VERSION ""

NS_ :

BS_:

BU_:
VAL_TABLE_ TIM_AuthErrorCode 39 "LwAPossibleBitMismatch" 38 "AuthenticationAbortedDueToGeneralPeerError" 37 "AuthenticationAbortedByPeerDueToError" 36 "ChallengeDataCorrupt" 35 "InvalidChallengeLength" 34 "FunctionFacilityNotCertified" 33 "RequestNotAllowed" 32 "Reserved_0x20" 31 "AuthenticationTimeout" 30 "CertificateTypeInvalid" 29 "DeviceCertificateRevoked" 28 "ManufacturerSeriesCertificateRevoked" 27 "ManufacturerCertificateRevoked" 26 "LabCertificateRevoked" 25 "RootCertificateRevoked" 24 "CertificateTypeMismatch" 23 "CertificateChainInvalid" 22 "ECU_CCID_Mismatch" 21 "NAME_Mismatch" 20 "ECC_PublicKeyValidationFailed" 19 "UnexpectedRestartAuthenticationBitSet" 18 "AuthenticationStatusInvalid" 17 "AuthenticationTypeNotSupported" 16 "AuthenticationStatusLost" 15 "DeviceCertificateDataCorrupt" 14 "ManufacturerSeriesCertificateDataCorrupt" 13 "ManufacturerCertificateDataCorrupt" 12 "TestLabCertificateDataCorrupt" 11 "RootCertificateDataCorrupt" 10 "InternalError" 9 "ChallengesDontMatch" 8 "DeviceCertificateSignatureInvalid" 7 "ManufacturerSeriesCertificateSignatureInvalid" 6 "ManufacturerCertificateSignatureInvalid" 5 "LabCertificateSignatureInvalid" 4 "RootCertificateSignatureInvalid" 3 "NotAuthenticationServerOrClient" 2 "CertificateFormatNotSupported" 1 "ParticipantBusy" 0 "NoError" ;
VAL_TABLE_ TIM_CertificateType 255 "NotAvailable" 6 "CRLCertificate" 5 "CRLSigningCertificate" 4 "DeviceCertificate" 3 "ManufacturerSeriesCertificate" 2 "ManufacturerCertificate" 1 "TestlabCertificate" 0 "AEFRootCertificate" ;
VAL_TABLE_ NetworkInterconnUnitParametrics 16 "NetworkInterconnectionUnitType" 15 "NumberOfPorts" 14 "UptimeSinceLastPowerOnReset " 13 "AverageNumOfMsgsFilteredPerSec" 12 "AverageNumOfMsgsForwardedPerSec" 11 "AverageNumOfMsgsReceivedPerSec" 10 "NumOfMsgsWithExcessTransitDelayTime " 9 "NumOfMsgsLostDueToBufferOverflow " 8 "AverageTransitDelayTime" 7 "MaxTransitDelayTime" 6 "MaxNumOfMsgsFilteredPerSec" 5 "MaxNumOfMsgsForwardedPerSec" 4 "MaxNumOfMsgsReceivedPerSec" 3 "NumberOfFilterDatabaseEntries" 2 "MaxFilterDatabaseSize" 1 "BufferSize" 0 "RequestAllParameters" ;
VAL_TABLE_ FMI 0 "Above normal (most severe)" 1 "Below normal (most severe)" 2 "Data erratic" 3 "Voltage above normal" 4 "Voltage below normal" 5 "Current below normal" 6 "Current above normal" 7 "Mechanical system not responding" 8 "Abnormal frequency" 9 "Abnormal update rate" 10 "Abnormal rate of change" 11 "Root cause not known" 12 "Bad intelligent device" 13 "Out of calibration" 14 "Special intstructions" 15 "Above normal (least severe)" 16 "Above normal (moderately severe)" 17 "Below normal (least severe)" 18 "Below normal (moderately severe)" 19 "Received network data in error" 31 "Condition exists" 20 "Data drifted high" 21 "Data drifted low" ;

BO_ 3221225472 VECTOR__INDEPENDENT_SIG_MSG: 0 Vector__XXX
 SG_ ISO15765_3 : 0|1@1+ (1,0) [0|1] "" Vector__XXX
 SG_ ISO14230 : 0|1@1+ (1,0) [0|1] "" Vector__XXX
 SG_ J1939_73 : 0|1@1+ (1,0) [0|1] "" Vector__XXX

BO_ 2566835198 DM2: 22 Vector__XXX
 SG_ SPN_High4 : 133|3@1+ (1,0) [0|7] "" Vector__XXX
 SG_ SPN_High3 : 101|3@1+ (1,0) [0|7] "" Vector__XXX
 SG_ SPN_High5 : 165|3@1+ (1,0) [0|7] "" Vector__XXX
 SG_ SPN_High2 : 69|3@1+ (1,0) [0|7] "" Vector__XXX
 SG_ SPN_High1 : 37|3@1+ (1,0) [0|7] "" Vector__XXX
 SG_ SpnConversionMethod1 : 47|1@1+ (1,0) [0|1] "" Vector__XXX
 SG_ SpnConversionMethod5 : 175|1@1+ (1,0) [0|1] "" Vector__XXX
 SG_ SpnConversionMethod4 : 143|1@1+ (1,0) [0|1] "" Vector__XXX
 SG_ SpnConversionMethod3 : 111|1@1+ (1,0) [0|1] "" Vector__XXX
 SG_ SpnConversionMethod2 : 79|1@1+ (1,0) [0|1] "" Vector__XXX
 SG_ OccurenceCount5 : 168|7@1+ (1,0) [0|127] "" Vector__XXX
 SG_ OccurenceCount4 : 136|7@1+ (1,0) [0|127] "" Vector__XXX
 SG_ OccurenceCount3 : 104|7@1+ (1,0) [0|127] "" Vector__XXX
 SG_ OccurenceCount2 : 72|7@1+ (1,0) [0|127] "" Vector__XXX
 SG_ OccurenceCount1 : 40|7@1+ (1,0) [0|127] "" Vector__XXX
 SG_ FMI5 : 160|5@1+ (1,0) [0|31] "" Vector__XXX
 SG_ FMI4 : 128|5@1+ (1,0) [0|31] "" Vector__XXX
 SG_ FMI3 : 96|5@1+ (1,0) [0|31] "" Vector__XXX
 SG_ FMI2 : 64|5@1+ (1,0) [0|31] "" Vector__XXX
 SG_ FMI1 : 32|5@1+ (1,0) [0|31] "" Vector__XXX
 SG_ SPN5 : 144|16@1+ (1,0) [0|524287] "" Vector__XXX
 SG_ SPN4 : 112|16@1+ (1,0) [0|524287] "" Vector__XXX
 SG_ SPN3 : 80|16@1+ (1,0) [0|524287] "" Vector__XXX
 SG_ SPN2 : 48|16@1+ (1,0) [0|524287] "" Vector__XXX
 SG_ SPN1 : 16|16@1+ (1,0) [0|524287] "" Vector__XXX

BO_ 2566834942 DM1: 22 Vector__XXX
 SG_ SPN_High4 : 133|3@1+ (1,0) [0|7] "" Vector__XXX
 SG_ SPN_High3 : 101|3@1+ (1,0) [0|7] "" Vector__XXX
 SG_ SPN_High5 : 165|3@1+ (1,0) [0|7] "" Vector__XXX
 SG_ SPN_High2 : 69|3@1+ (1,0) [0|7] "" Vector__XXX
 SG_ SPN_High1 : 37|3@1+ (1,0) [0|7] "" Vector__XXX
 SG_ SpnConversionMethod1 : 47|1@1+ (1,0) [0|1] "" Vector__XXX
 SG_ SpnConversionMethod5 : 175|1@1+ (1,0) [0|1] "" Vector__XXX
 SG_ SpnConversionMethod4 : 143|1@1+ (1,0) [0|1] "" Vector__XXX
 SG_ SpnConversionMethod3 : 111|1@1+ (1,0) [0|1] "" Vector__XXX
 SG_ SpnConversionMethod2 : 79|1@1+ (1,0) [0|1] "" Vector__XXX
 SG_ OccurenceCount5 : 168|7@1+ (1,0) [0|127] "" Vector__XXX
 SG_ OccurenceCount4 : 136|7@1+ (1,0) [0|127] "" Vector__XXX
 SG_ OccurenceCount3 : 104|7@1+ (1,0) [0|127] "" Vector__XXX
 SG_ OccurenceCount2 : 72|7@1+ (1,0) [0|127] "" Vector__XXX
 SG_ OccurenceCount1 : 40|7@1+ (1,0) [0|127] "" Vector__XXX
 SG_ FMI5 : 160|5@1+ (1,0) [0|31] "" Vector__XXX
 SG_ FMI4 : 128|5@1+ (1,0) [0|31] "" Vector__XXX
 SG_ FMI3 : 96|5@1+ (1,0) [0|31] "" Vector__XXX
 SG_ FMI2 : 64|5@1+ (1,0) [0|31] "" Vector__XXX
 SG_ FMI1 : 32|5@1+ (1,0) [0|31] "" Vector__XXX
 SG_ SPN5 : 144|16@1+ (1,0) [0|524287] "" Vector__XXX
 SG_ SPN4 : 112|16@1+ (1,0) [0|524287] "" Vector__XXX
 SG_ SPN3 : 80|16@1+ (1,0) [0|524287] "" Vector__XXX
 SG_ SPN2 : 48|16@1+ (1,0) [0|524287] "" Vector__XXX
 SG_ SPN1 : 16|16@1+ (1,0) [0|524287] "" Vector__XXX

BO_ 2566655998 SHRPS: 8 Vector__XXX
 SG_ FrontHitchPitchSensitivity : 8|8@1+ (0.4,0) [0|100] "%" Vector__XXX
 SG_ FrontHitchRollSensitivity : 0|8@1+ (0.4,0) [0|100] "%" Vector__XXX

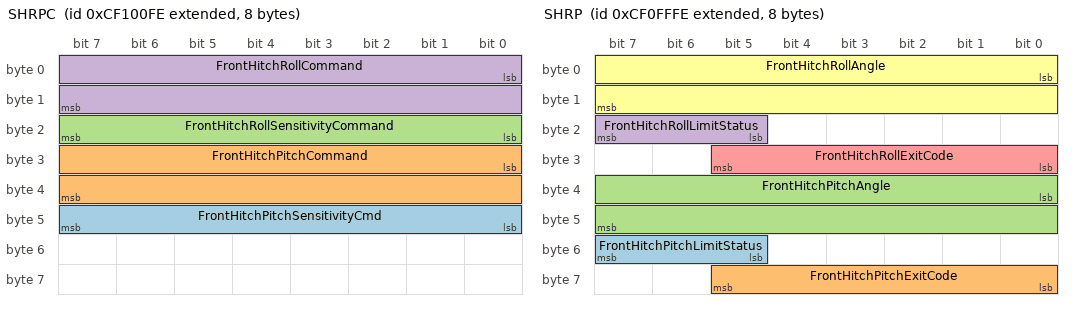
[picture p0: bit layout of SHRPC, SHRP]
BO_ 2364604670 SHRPC: 8 Vector__XXX
 SG_ FrontHitchPitchSensitivityCmd : 40|8@1+ (0.4,0) [0|100] "%" Vector__XXX
 SG_ FrontHitchPitchCommand : 24|16@1+ (0.002,-64) [-64|64.51] "deg" Vector__XXX
 SG_ FrontHitchRollSensitivityCommand : 16|8@1+ (0.4,0) [0|100] "%" Vector__XXX
 SG_ FrontHitchRollCommand : 0|16@1+ (0.002,-64) [-64|64.51] "deg" Vector__XXX

BO_ 2364604414 SHRP: 8 Vector__XXX
 SG_ FrontHitchPitchLimitStatus : 53|3@1+ (1,0) [0|7] "" Vector__XXX
 SG_ FrontHitchPitchExitCode : 56|6@1+ (1,0) [0|63] "" Vector__XXX
 SG_ FrontHitchPitchAngle : 32|16@1+ (0.002,-64) [-64|64.51] "deg" Vector__XXX
 SG_ FrontHitchRollLimitStatus : 21|3@1+ (1,0) [0|7] "" Vector__XXX
 SG_ FrontHitchRollExitCode : 24|6@1+ (1,0) [0|63] "" Vector__XXX
 SG_ FrontHitchRollAngle : 0|16@1+ (0.002,-64) [-64|64.51] "deg" Vector__XXX

BO_ 2566655742 PHRPS: 8 Vector__XXX
 SG_ RearHitchPitchSensitivity : 8|8@1+ (0.4,0) [0|100] "%" Vector__XXX
 SG_ RearHitchRollSensitivity : 0|8@1+ (0.4,0) [0|100] "%" Vector__XXX

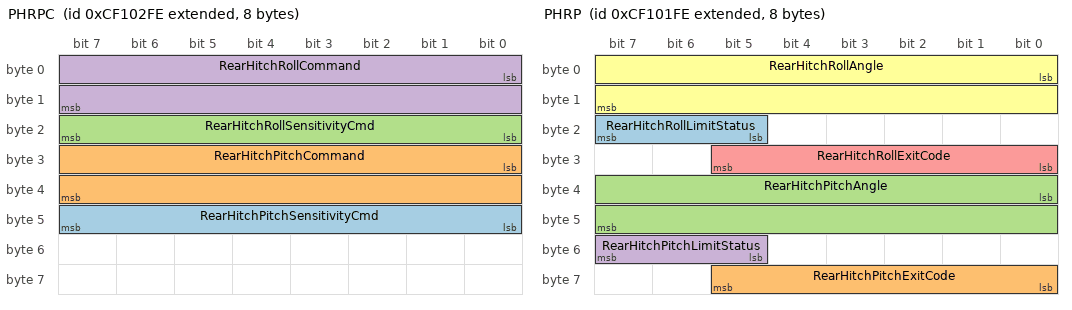
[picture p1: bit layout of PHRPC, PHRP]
BO_ 2364605182 PHRPC: 8 Vector__XXX
 SG_ RearHitchPitchSensitivityCmd : 40|8@1+ (0.4,0) [0|100] "%" Vector__XXX
 SG_ RearHitchPitchCommand : 24|16@1+ (0.002,-64) [-64|64.51] "deg" Vector__XXX
 SG_ RearHitchRollSensitivityCmd : 16|8@1+ (0.4,0) [0|100] "%" Vector__XXX
 SG_ RearHitchRollCommand : 0|16@1+ (0.002,-64) [-64|64.51] "deg" Vector__XXX

BO_ 2364604926 PHRP: 8 Vector__XXX
 SG_ RearHitchRollLimitStatus : 21|3@1+ (1,0) [0|7] "" Vector__XXX
 SG_ RearHitchPitchExitCode : 56|6@1+ (1,0) [0|63] "" Vector__XXX
 SG_ RearHitchPitchAngle : 32|16@1+ (0.002,-64) [-64|64.51] "deg" Vector__XXX
 SG_ RearHitchPitchLimitStatus : 53|3@1+ (1,0) [0|7] "" Vector__XXX
 SG_ RearHitchRollExitCode : 24|6@1+ (1,0) [0|0] "" Vector__XXX
 SG_ RearHitchRollAngle : 0|16@1+ (0.002,-64) [-64|64.51] "deg" Vector__XXX

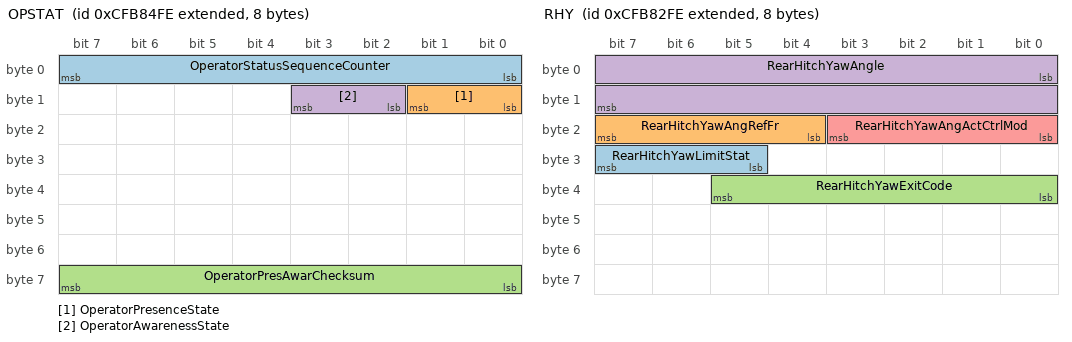
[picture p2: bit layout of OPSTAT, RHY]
BO_ 2365293822 OPSTAT: 8 Vector__XXX
 SG_ OperatorStatusSequenceCounter : 0|8@1+ (1,0) [0|255] "" Vector__XXX
 SG_ OperatorPresenceState : 8|2@1+ (1,0) [0|0] "" Vector__XXX
 SG_ OperatorPresAwarChecksum : 56|8@1+ (1,0) [0|255] "" Vector__XXX
 SG_ OperatorAwarenessState : 10|2@1+ (1,0) [0|3] "" Vector__XXX

BO_ 2365293310 RHY: 8 Vector__XXX
 SG_ RearHitchYawLimitStat : 29|3@1+ (1,0) [0|7] "" Vector__XXX
 SG_ RearHitchYawAngRefFr : 20|4@1+ (1,0) [0|15] "" Vector__XXX
 SG_ RearHitchYawExitCode : 32|6@1+ (1,0) [0|63] "" Vector__XXX
 SG_ RearHitchYawAngle : 0|16@1+ (0.0078125,-200) [-200|200] "deg" Vector__XXX
 SG_ RearHitchYawAngActCtrlMod : 16|4@1+ (1,0) [0|15] "" Vector__XXX

BO_ 2364620542 FHYC: 8 Vector__XXX
 SG_ FrontHitchYawCommand : 0|16@1+ (0.0078125,-200) [-200|200] "deg" Vector__XXX

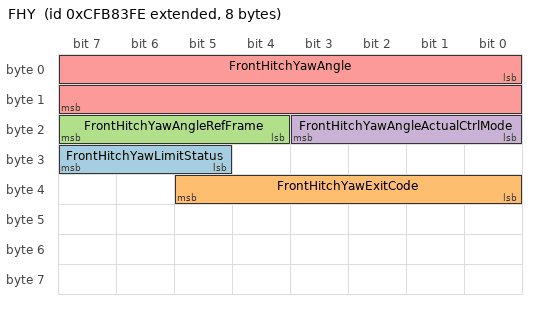
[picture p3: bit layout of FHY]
BO_ 2365293566 FHY: 8 Vector__XXX
 SG_ FrontHitchYawLimitStatus : 29|3@1+ (1,0) [0|7] "" Vector__XXX
 SG_ FrontHitchYawExitCode : 32|6@1+ (1,0) [0|63] "" Vector__XXX
 SG_ FrontHitchYawAngleRefFrame : 20|4@1+ (1,0) [0|15] "" Vector__XXX
 SG_ FrontHitchYawAngleActualCtrlMode : 16|4@1+ (1,0) [0|15] "" Vector__XXX
 SG_ FrontHitchYawAngle : 0|16@1+ (0.0078125,-200) [-200|200] "deg" Vector__XXX

BO_ 2566730494 ECUDP: 8 Vector__XXX
 SG_ DiagProtocolIdentification : 0|8@1+ (1,0) [0|255] "" Vector__XXX

BO_ 2625437438 ECFF: 8 Vector__XXX

BO_ 2364620798 RHYC: 8 Vector__XXX
 SG_ RearHitchYawCommand : 0|16@1+ (0.0078125,-200) [-200|200] "deg" Vector__XXX

BO_ 2621308670 TIM21_CS: 16 Vector__XXX
 SG_ VSpeedIncAggressivenessReq_VS m65 : 16|16@1+ (0.001,0) [0|64.255] "m/s per sec." Vector__XXX
 SG_ VSpeedDecAggressivenessReq_VS m65 : 32|16@1+ (0.001,0) [0|64.255] "m/s per sec." Vector__XXX
 SG_ RSpeedIncAggressivenessReq_RPTO m65 : 16|16@1+ (0.125,0) [0|8031.875] "1/min per sec." Vector__XXX
 SG_ RSpeedIncAggressivenessReq_FPTO m65 : 16|16@1+ (0.125,0) [0|8031.875] "1/min per sec." Vector__XXX
 SG_ RSpeedDecAggressivenessReq_RPTO m65 : 32|16@1+ (0.125,0) [0|8031.875] "1/min per sec." Vector__XXX
 SG_ RSpeedDecAggressivenessReq_FPTO m65 : 32|16@1+ (0.125,0) [0|8031.875] "1/min per sec." Vector__XXX
 SG_ PositionIncAggressivenessReq_RTL m65 : 16|16@1+ (0.01,0) [0|100] "% per sec." Vector__XXX
 SG_ PositionIncAggressivenessReq_RH m65 : 16|16@1+ (0.01,0) [0|100] "% per sec." Vector__XXX
 SG_ PositionIncAggressivenessReq_FTL m65 : 16|16@1+ (0.01,0) [0|100] "% per sec." Vector__XXX
 SG_ PositionIncAggressivenessReq_FH m65 : 16|16@1+ (0.01,0) [0|100] "% per sec." Vector__XXX
 SG_ PositionDecAggressivenessReq_RTL m65 : 32|16@1+ (0.01,0) [0|100] "% per sec." Vector__XXX
 SG_ PositionDecAggressivenessReq_RH m65 : 32|16@1+ (0.01,0) [0|100] "% per sec." Vector__XXX
 SG_ PositionDecAggressivenessReq_FTL m65 : 32|16@1+ (0.01,0) [0|100] "% per sec." Vector__XXX
 SG_ PositionDecAggressivenessReq_FH m65 : 32|16@1+ (0.01,0) [0|100] "% per sec." Vector__XXX
 SG_ FlowIncAggressivenessReq_AV32 m65 : 16|16@1+ (0.004,0) [0|257.016] "% per sec." Vector__XXX
 SG_ FlowIncAggressivenessReq_AV31 m65 : 16|16@1+ (0.004,0) [0|257.016] "% per sec." Vector__XXX
 SG_ FlowIncAggressivenessReq_AV30 m65 : 16|16@1+ (0.004,0) [0|257.016] "% per sec." Vector__XXX
 SG_ FlowIncAggressivenessReq_AV29 m65 : 16|16@1+ (0.004,0) [0|257.016] "% per sec." Vector__XXX
 SG_ FlowIncAggressivenessReq_AV28 m65 : 16|16@1+ (0.004,0) [0|257.016] "% per sec." Vector__XXX
 SG_ FlowIncAggressivenessReq_AV27 m65 : 16|16@1+ (0.004,0) [0|257.016] "% per sec." Vector__XXX
 SG_ FlowIncAggressivenessReq_AV26 m65 : 16|16@1+ (0.004,0) [0|257.016] "% per sec." Vector__XXX
 SG_ FlowIncAggressivenessReq_AV25 m65 : 16|16@1+ (0.004,0) [0|257.016] "% per sec." Vector__XXX
 SG_ FlowIncAggressivenessReq_AV24 m65 : 16|16@1+ (0.004,0) [0|257.016] "% per sec." Vector__XXX
 SG_ FlowIncAggressivenessReq_AV23 m65 : 16|16@1+ (0.004,0) [0|257.016] "% per sec." Vector__XXX
 SG_ FlowIncAggressivenessReq_AV22 m65 : 16|16@1+ (0.004,0) [0|257.016] "% per sec." Vector__XXX
 SG_ FlowIncAggressivenessReq_AV21 m65 : 16|16@1+ (0.004,0) [0|257.016] "% per sec." Vector__XXX
 SG_ FlowIncAggressivenessReq_AV20 m65 : 16|16@1+ (0.004,0) [0|257.016] "% per sec." Vector__XXX
 SG_ FlowIncAggressivenessReq_AV19 m65 : 16|16@1+ (0.004,0) [0|257.016] "% per sec." Vector__XXX
 SG_ FlowIncAggressivenessReq_AV18 m65 : 16|16@1+ (0.004,0) [0|257.016] "% per sec." Vector__XXX
 SG_ FlowIncAggressivenessReq_AV17 m65 : 16|16@1+ (0.004,0) [0|257.016] "% per sec." Vector__XXX
 SG_ FlowIncAggressivenessReq_AV16 m65 : 16|16@1+ (0.004,0) [0|257.016] "% per sec." Vector__XXX
 SG_ FlowIncAggressivenessReq_AV15 m65 : 16|16@1+ (0.004,0) [0|257.016] "% per sec." Vector__XXX
 SG_ FlowIncAggressivenessReq_AV14 m65 : 16|16@1+ (0.004,0) [0|257.016] "% per sec." Vector__XXX
 SG_ FlowIncAggressivenessReq_AV13 m65 : 16|16@1+ (0.004,0) [0|257.016] "% per sec." Vector__XXX
 SG_ FlowIncAggressivenessReq_AV12 m65 : 16|16@1+ (0.004,0) [0|257.016] "% per sec." Vector__XXX
 SG_ FlowIncAggressivenessReq_AV11 m65 : 16|16@1+ (0.004,0) [0|257.016] "% per sec." Vector__XXX
 SG_ FlowIncAggressivenessReq_AV10 m65 : 16|16@1+ (0.004,0) [0|257.016] "% per sec." Vector__XXX
 SG_ FlowIncAggressivenessReq_AV09 m65 : 16|16@1+ (0.004,0) [0|257.016] "% per sec." Vector__XXX
 SG_ FlowIncAggressivenessReq_AV08 m65 : 16|16@1+ (0.004,0) [0|257.016] "% per sec." Vector__XXX
 SG_ FlowIncAggressivenessReq_AV07 m65 : 16|16@1+ (0.004,0) [0|257.016] "% per sec." Vector__XXX
 SG_ FlowIncAggressivenessReq_AV06 m65 : 16|16@1+ (0.004,0) [0|257.016] "% per sec." Vector__XXX
 SG_ FlowIncAggressivenessReq_AV05 m65 : 16|16@1+ (0.004,0) [0|257.016] "% per sec." Vector__XXX
 SG_ FlowIncAggressivenessReq_AV04 m65 : 16|16@1+ (0.004,0) [0|257.016] "% per sec." Vector__XXX
 SG_ FlowIncAggressivenessReq_AV03 m65 : 16|16@1+ (0.004,0) [0|257.016] "% per sec." Vector__XXX
 SG_ FlowIncAggressivenessReq_AV02 m65 : 16|16@1+ (0.004,0) [0|257.016] "% per sec." Vector__XXX
 SG_ FlowIncAggressivenessReq_AV01 m65 : 16|16@1+ (0.004,0) [0|257.016] "% per sec." Vector__XXX
 SG_ FlowDecAggressivenessReq_AV32 m65 : 32|16@1+ (0.004,0) [0|257.016] "% per sec." Vector__XXX
 SG_ FlowDecAggressivenessReq_AV31 m65 : 32|16@1+ (0.004,0) [0|257.016] "% per sec." Vector__XXX
 SG_ FlowDecAggressivenessReq_AV30 m65 : 32|16@1+ (0.004,0) [0|257.016] "% per sec." Vector__XXX
 SG_ FlowDecAggressivenessReq_AV29 m65 : 32|16@1+ (0.004,0) [0|257.016] "% per sec." Vector__XXX
 SG_ FlowDecAggressivenessReq_AV28 m65 : 32|16@1+ (0.004,0) [0|257.016] "% per sec." Vector__XXX
 SG_ FlowDecAggressivenessReq_AV27 m65 : 32|16@1+ (0.004,0) [0|257.016] "% per sec." Vector__XXX
 SG_ FlowDecAggressivenessReq_AV26 m65 : 32|16@1+ (0.004,0) [0|257.016] "% per sec." Vector__XXX
 SG_ FlowDecAggressivenessReq_AV25 m65 : 32|16@1+ (0.004,0) [0|257.016] "% per sec." Vector__XXX
 SG_ FlowDecAggressivenessReq_AV24 m65 : 32|16@1+ (0.004,0) [0|257.016] "% per sec." Vector__XXX
 SG_ FlowDecAggressivenessReq_AV23 m65 : 32|16@1+ (0.004,0) [0|257.016] "% per sec." Vector__XXX
 SG_ FlowDecAggressivenessReq_AV22 m65 : 32|16@1+ (0.004,0) [0|257.016] "% per sec." Vector__XXX
 SG_ FlowDecAggressivenessReq_AV21 m65 : 32|16@1+ (0.004,0) [0|257.016] "% per sec." Vector__XXX
 SG_ FlowDecAggressivenessReq_AV20 m65 : 32|16@1+ (0.004,0) [0|257.016] "% per sec." Vector__XXX
 SG_ FlowDecAggressivenessReq_AV19 m65 : 32|16@1+ (0.004,0) [0|257.016] "% per sec." Vector__XXX
 SG_ FlowDecAggressivenessReq_AV18 m65 : 32|16@1+ (0.004,0) [0|257.016] "% per sec." Vector__XXX
 SG_ FlowDecAggressivenessReq_AV17 m65 : 32|16@1+ (0.004,0) [0|257.016] "% per sec." Vector__XXX
 SG_ FlowDecAggressivenessReq_AV16 m65 : 32|16@1+ (0.004,0) [0|257.016] "% per sec." Vector__XXX
 SG_ FlowDecAggressivenessReq_AV15 m65 : 32|16@1+ (0.004,0) [0|257.016] "% per sec." Vector__XXX
 SG_ FlowDecAggressivenessReq_AV14 m65 : 32|16@1+ (0.004,0) [0|257.016] "% per sec." Vector__XXX
 SG_ FlowDecAggressivenessReq_AV13 m65 : 32|16@1+ (0.004,0) [0|257.016] "% per sec." Vector__XXX
 SG_ FlowDecAggressivenessReq_AV12 m65 : 32|16@1+ (0.004,0) [0|257.016] "% per sec." Vector__XXX
 SG_ FlowDecAggressivenessReq_AV11 m65 : 32|16@1+ (0.004,0) [0|257.016] "% per sec." Vector__XXX
 SG_ FlowDecAggressivenessReq_AV10 m65 : 32|16@1+ (0.004,0) [0|257.016] "% per sec." Vector__XXX
 SG_ FlowDecAggressivenessReq_AV09 m65 : 32|16@1+ (0.004,0) [0|257.016] "% per sec." Vector__XXX
 SG_ FlowDecAggressivenessReq_AV08 m65 : 32|16@1+ (0.004,0) [0|257.016] "% per sec." Vector__XXX
 SG_ FlowDecAggressivenessReq_AV07 m65 : 32|16@1+ (0.004,0) [0|257.016] "% per sec." Vector__XXX
 SG_ FlowDecAggressivenessReq_AV06 m65 : 32|16@1+ (0.004,0) [0|257.016] "% per sec." Vector__XXX
 SG_ FlowDecAggressivenessReq_AV05 m65 : 32|16@1+ (0.004,0) [0|257.016] "% per sec." Vector__XXX
 SG_ FlowDecAggressivenessReq_AV04 m65 : 32|16@1+ (0.004,0) [0|257.016] "% per sec." Vector__XXX
 SG_ FlowDecAggressivenessReq_AV03 m65 : 32|16@1+ (0.004,0) [0|257.016] "% per sec." Vector__XXX
 SG_ FlowDecAggressivenessReq_AV02 m65 : 32|16@1+ (0.004,0) [0|257.016] "% per sec." Vector__XXX
 SG_ FlowDecAggressivenessReq_AV01 m65 : 32|16@1+ (0.004,0) [0|257.016] "% per sec." Vector__XXX
 SG_ CurvatureAggressivenessReq_EG m65 : 16|16@1+ (0.25,0) [0|16063.75] "1/km per sec." Vector__XXX
 SG_ SecurityByte_VS m17 : 56|8@1+ (1,0) [0|255] "" Vector__XXX
 SG_ SecurityByte_RTL m17 : 56|8@1+ (1,0) [0|255] "" Vector__XXX
 SG_ SecurityByte_RPTO m17 : 56|8@1+ (1,0) [0|255] "" Vector__XXX
 SG_ SecurityByte_RH m17 : 56|8@1+ (1,0) [0|255] "" Vector__XXX
 SG_ SecurityByte_FTL m17 : 56|8@1+ (1,0) [0|255] "" Vector__XXX
 SG_ SecurityByte_FPTO m17 : 56|8@1+ (1,0) [0|255] "" Vector__XXX
 SG_ SecurityByte_FH m17 : 56|8@1+ (1,0) [0|255] "" Vector__XXX
 SG_ SecurityByte_EG m17 : 56|8@1+ (1,0) [0|255] "" Vector__XXX
 SG_ SecurityByte_AV32 m17 : 56|8@1+ (1,0) [0|255] "" Vector__XXX
 SG_ SecurityByte_AV31 m17 : 56|8@1+ (1,0) [0|255] "" Vector__XXX
 SG_ SecurityByte_AV30 m17 : 56|8@1+ (1,0) [0|255] "" Vector__XXX
 SG_ SecurityByte_AV29 m17 : 56|8@1+ (1,0) [0|255] "" Vector__XXX
 SG_ SecurityByte_AV28 m17 : 56|8@1+ (1,0) [0|255] "" Vector__XXX
 SG_ SecurityByte_AV27 m17 : 56|8@1+ (1,0) [0|255] "" Vector__XXX
 SG_ SecurityByte_AV26 m17 : 56|8@1+ (1,0) [0|255] "" Vector__XXX
 SG_ SecurityByte_AV25 m17 : 56|8@1+ (1,0) [0|255] "" Vector__XXX
 SG_ SecurityByte_AV24 m17 : 56|8@1+ (1,0) [0|255] "" Vector__XXX
 SG_ SecurityByte_AV23 m17 : 56|8@1+ (1,0) [0|255] "" Vector__XXX
 SG_ SecurityByte_AV22 m17 : 56|8@1+ (1,0) [0|255] "" Vector__XXX
 SG_ SecurityByte_AV21 m17 : 56|8@1+ (1,0) [0|255] "" Vector__XXX
 SG_ SecurityByte_AV20 m17 : 56|8@1+ (1,0) [0|255] "" Vector__XXX
 SG_ SecurityByte_AV19 m17 : 56|8@1+ (1,0) [0|255] "" Vector__XXX
 SG_ SecurityByte_AV18 m17 : 56|8@1+ (1,0) [0|255] "" Vector__XXX
 SG_ SecurityByte_AV17 m17 : 56|8@1+ (1,0) [0|255] "" Vector__XXX
 SG_ SecurityByte_AV16 m17 : 56|8@1+ (1,0) [0|255] "" Vector__XXX
 SG_ SecurityByte_AV15 m17 : 56|8@1+ (1,0) [0|255] "" Vector__XXX
 SG_ SecurityByte_AV14 m17 : 56|8@1+ (1,0) [0|255] "" Vector__XXX
 SG_ SecurityByte_AV13 m17 : 56|8@1+ (1,0) [0|255] "" Vector__XXX
 SG_ SecurityByte_AV12 m17 : 56|8@1+ (1,0) [0|255] "" Vector__XXX
 SG_ SecurityByte_AV11 m17 : 56|8@1+ (1,0) [0|255] "" Vector__XXX
 SG_ SecurityByte_AV10 m17 : 56|8@1+ (1,0) [0|255] "" Vector__XXX
 SG_ SecurityByte_AV09 m17 : 56|8@1+ (1,0) [0|255] "" Vector__XXX
 SG_ SecurityByte_AV08 m17 : 56|8@1+ (1,0) [0|255] "" Vector__XXX
 SG_ SecurityByte_AV07 m17 : 56|8@1+ (1,0) [0|255] "" Vector__XXX
 SG_ SecurityByte_AV06 m17 : 56|8@1+ (1,0) [0|255] "" Vector__XXX
 SG_ SecurityByte_AV05 m17 : 56|8@1+ (1,0) [0|255] "" Vector__XXX
 SG_ SecurityByte_AV04 m17 : 56|8@1+ (1,0) [0|255] "" Vector__XXX
 SG_ SecurityByte_AV03 m17 : 56|8@1+ (1,0) [0|255] "" Vector__XXX
 SG_ SecurityByte_AV02 m17 : 56|8@1+ (1,0) [0|255] "" Vector__XXX
 SG_ SecurityByte_AV01 m17 : 56|8@1+ (1,0) [0|255] "" Vector__XXX
 SG_ PositionRequest_RTL m17 : 32|16@1+ (0.01,0) [0|100] "%" Vector__XXX
 SG_ PositionRequest_FTL m17 : 32|16@1+ (0.01,0) [0|100] "%" Vector__XXX
 SG_ ControlMode1_VS m0M : 24|4@1+ (1,0) [0|15] "" Vector__XXX
 SG_ ControlMode1_RTL m0M : 24|4@1+ (1,0) [0|15] "" Vector__XXX
 SG_ ControlMode1_FTL m0M : 24|4@1+ (1,0) [0|15] "" Vector__XXX
 SG_ NumOfControlModes_VS m0 : 16|4@1+ (1,0) [0|15] "" Vector__XXX
 SG_ NumOfControlModes_RTL m0 : 16|4@1+ (1,0) [0|15] "" Vector__XXX
 SG_ NumOfControlModes_FTL m0 : 16|4@1+ (1,0) [0|15] "" Vector__XXX
 SG_ NumOfBytes_CM1_VS m0 : 32|8@1+ (1,0) [0|255] "" Vector__XXX
 SG_ NumOfBytes_CM1_RTL m0 : 32|8@1+ (1,0) [0|255] "" Vector__XXX
 SG_ NumOfBytes_CM1_FTL m0 : 32|8@1+ (1,0) [0|255] "" Vector__XXX
 SG_ MsgType_RTL m72M : 8|8@1+ (1,0) [0|255] "" Vector__XXX
 SG_ MsgType_FTL m71M : 8|8@1+ (1,0) [0|255] "" Vector__XXX
 SG_ MsgType_EG m70M : 8|8@1+ (1,0) [0|255] "" Vector__XXX
 SG_ MsgType_VS m68M : 8|8@1+ (1,0) [0|255] "" Vector__XXX
 SG_ MsgType_RH m67M : 8|8@1+ (1,0) [0|255] "" Vector__XXX
 SG_ MsgType_FH m66M : 8|8@1+ (1,0) [0|255] "" Vector__XXX
 SG_ MsgType_RPTO m65M : 8|8@1+ (1,0) [0|255] "" Vector__XXX
 SG_ MsgType_FPTO m64M : 8|8@1+ (1,0) [0|255] "" Vector__XXX
 SG_ MsgType_AV32 m32M : 8|8@1+ (1,0) [0|255] "" Vector__XXX
 SG_ MsgType_AV31 m31M : 8|8@1+ (1,0) [0|255] "" Vector__XXX
 SG_ MsgType_AV30 m30M : 8|8@1+ (1,0) [0|255] "" Vector__XXX
 SG_ MsgType_AV29 m29M : 8|8@1+ (1,0) [0|255] "" Vector__XXX
 SG_ MsgType_AV28 m28M : 8|8@1+ (1,0) [0|255] "" Vector__XXX
 SG_ MsgType_AV27 m27M : 8|8@1+ (1,0) [0|255] "" Vector__XXX
 SG_ MsgType_AV26 m26M : 8|8@1+ (1,0) [0|255] "" Vector__XXX
 SG_ MsgType_AV25 m25M : 8|8@1+ (1,0) [0|255] "" Vector__XXX
 SG_ MsgType_AV24 m24M : 8|8@1+ (1,0) [0|255] "" Vector__XXX
 SG_ MsgType_AV23 m23M : 8|8@1+ (1,0) [0|255] "" Vector__XXX
 SG_ MsgType_AV22 m22M : 8|8@1+ (1,0) [0|255] "" Vector__XXX
 SG_ MsgType_AV21 m21M : 8|8@1+ (1,0) [0|255] "" Vector__XXX
 SG_ MsgType_AV20 m20M : 8|8@1+ (1,0) [0|255] "" Vector__XXX
 SG_ MsgType_AV19 m19M : 8|8@1+ (1,0) [0|255] "" Vector__XXX
 SG_ MsgType_AV18 m18M : 8|8@1+ (1,0) [0|255] "" Vector__XXX
 SG_ MsgType_AV17 m17M : 8|8@1+ (1,0) [0|255] "" Vector__XXX
 SG_ MsgType_AV16 m16M : 8|8@1+ (1,0) [0|255] "" Vector__XXX
 SG_ MsgType_AV15 m15M : 8|8@1+ (1,0) [0|255] "" Vector__XXX
 SG_ MsgType_AV14 m14M : 8|8@1+ (1,0) [0|255] "" Vector__XXX
 SG_ MsgType_AV13 m13M : 8|8@1+ (1,0) [0|255] "" Vector__XXX
 SG_ MsgType_AV12 m12M : 8|8@1+ (1,0) [0|255] "" Vector__XXX
 SG_ MsgType_AV11 m11M : 8|8@1+ (1,0) [0|255] "" Vector__XXX
 SG_ MsgType_AV10 m10M : 8|8@1+ (1,0) [0|255] "" Vector__XXX
 SG_ MsgType_AV09 m9M : 8|8@1+ (1,0) [0|255] "" Vector__XXX
 SG_ MsgType_AV08 m8M : 8|8@1+ (1,0) [0|255] "" Vector__XXX
 SG_ MsgType_AV07 m7M : 8|8@1+ (1,0) [0|255] "" Vector__XXX
 SG_ MsgType_AV06 m6M : 8|8@1+ (1,0) [0|255] "" Vector__XXX
 SG_ MsgType_AV05 m5M : 8|8@1+ (1,0) [0|255] "" Vector__XXX
 SG_ MsgType_AV04 m4M : 8|8@1+ (1,0) [0|255] "" Vector__XXX
 SG_ MsgType_AV03 m3M : 8|8@1+ (1,0) [0|255] "" Vector__XXX
 SG_ MsgType_AV02 m2M : 8|8@1+ (1,0) [0|255] "" Vector__XXX
 SG_ MsgType_AV01 m1M : 8|8@1+ (1,0) [0|255] "" Vector__XXX
 SG_ TIMFunctionID M : 0|8@1+ (1,0) [0|255] "" Vector__XXX
 SG_ FlowRequest_AV32 m17 : 32|16@1+ (0.004,-128.512) [0|0] "%" Vector__XXX
 SG_ FlowRequest_AV31 m17 : 32|16@1+ (0.004,-128.512) [0|0] "%" Vector__XXX
 SG_ FlowRequest_AV30 m17 : 32|16@1+ (0.004,-128.512) [0|0] "%" Vector__XXX
 SG_ FlowRequest_AV29 m17 : 32|16@1+ (0.004,-128.512) [0|0] "%" Vector__XXX
 SG_ FlowRequest_AV28 m17 : 32|16@1+ (0.004,-128.512) [0|0] "%" Vector__XXX
 SG_ FlowRequest_AV27 m17 : 32|16@1+ (0.004,-128.512) [0|0] "%" Vector__XXX
 SG_ FlowRequest_AV26 m17 : 32|16@1+ (0.004,-128.512) [0|0] "%" Vector__XXX
 SG_ FlowRequest_AV25 m17 : 32|16@1+ (0.004,-128.512) [0|0] "%" Vector__XXX
 SG_ FlowRequest_AV24 m17 : 32|16@1+ (0.004,-128.512) [0|0] "%" Vector__XXX
 SG_ FlowRequest_AV23 m17 : 32|16@1+ (0.004,-128.512) [0|0] "%" Vector__XXX
 SG_ FlowRequest_AV22 m17 : 32|16@1+ (0.004,-128.512) [0|0] "%" Vector__XXX
 SG_ FlowRequest_AV21 m17 : 32|16@1+ (0.004,-128.512) [0|0] "%" Vector__XXX
 SG_ FlowRequest_AV20 m17 : 32|16@1+ (0.004,-128.512) [0|0] "%" Vector__XXX
 SG_ FlowRequest_AV19 m17 : 32|16@1+ (0.004,-128.512) [0|0] "%" Vector__XXX
 SG_ FlowRequest_AV18 m17 : 32|16@1+ (0.004,-128.512) [0|0] "%" Vector__XXX
 SG_ FlowRequest_AV17 m17 : 32|16@1+ (0.004,-128.512) [0|0] "%" Vector__XXX
 SG_ FlowRequest_AV16 m17 : 32|16@1+ (0.004,-128.512) [0|0] "%" Vector__XXX
 SG_ FlowRequest_AV15 m17 : 32|16@1+ (0.004,-128.512) [0|0] "%" Vector__XXX
 SG_ FlowRequest_AV14 m17 : 32|16@1+ (0.004,-128.512) [0|0] "%" Vector__XXX
 SG_ FlowRequest_AV13 m17 : 32|16@1+ (0.004,-128.512) [0|0] "%" Vector__XXX
 SG_ FlowRequest_AV12 m17 : 32|16@1+ (0.004,-128.512) [0|0] "%" Vector__XXX
 SG_ FlowRequest_AV11 m17 : 32|16@1+ (0.004,-128.512) [0|0] "%" Vector__XXX
 SG_ FlowRequest_AV10 m17 : 32|16@1+ (0.004,-128.512) [0|0] "%" Vector__XXX
 SG_ FlowRequest_AV09 m17 : 32|16@1+ (0.004,-128.512) [0|0] "%" Vector__XXX
 SG_ FlowRequest_AV08 m17 : 32|16@1+ (0.004,-128.512) [0|0] "%" Vector__XXX
 SG_ FlowRequest_AV07 m17 : 32|16@1+ (0.004,-128.512) [0|0] "%" Vector__XXX
 SG_ FlowRequest_AV06 m17 : 32|16@1+ (0.004,-128.512) [0|0] "%" Vector__XXX
 SG_ FlowRequest_AV05 m17 : 32|16@1+ (0.004,-128.512) [0|0] "%" Vector__XXX
 SG_ FlowRequest_AV04 m17 : 32|16@1+ (0.004,-128.512) [0|0] "%" Vector__XXX
 SG_ FlowRequest_AV03 m17 : 32|16@1+ (0.004,-128.512) [0|0] "%" Vector__XXX
 SG_ FlowRequest_AV02 m17 : 32|16@1+ (0.004,-128.512) [0|0] "%" Vector__XXX
 SG_ PositionRequest_RH m17 : 32|16@1+ (0.01,0) [0|100] "%" Vector__XXX
 SG_ OutputShaftSpeedRequest_RPTO m17 : 32|16@1+ (0.125,-4016) [0|0] "1/min" Vector__XXX
 SG_ CurvatureRequest_EG m17 : 32|16@1+ (0.25,-8032) [-8032|8031.75] "1/km" Vector__XXX
 SG_ VehicleSpeedRequest_VS m17 : 32|16@1+ (0.001,-32.128) [-32.127|32.127] "m/s" Vector__XXX
 SG_ PositionRequest_FH m17 : 32|16@1+ (0.01,0) [0|100] "%" Vector__XXX
 SG_ OutputShaftSpeedRequest_FPTO m17 : 32|16@1+ (0.125,-4016) [0|0] "1/min" Vector__XXX
 SG_ FlowRequest_AV01 m17 : 32|16@1+ (0.004,-128.512) [0|0] "%" Vector__XXX

CM_ BO_ 3221225472 "This is a message for not used signals, created by Vector CANdb++ DBC OLE DB Provider.";
CM_ SG_ 3221225472 ISO15765_3 "ISO 15765-3 (UDS on CAN)";
CM_ SG_ 3221225472 ISO14230 "ISO 14230 (KWP 2000 over K line)";
CM_ SG_ 3221225472 J1939_73 "J1939-73";
CM_ BO_ 2566835198 "Previously Active Diagnostic Trouble Codes
The information communicated is DM service to communicate the previously active trouble codes.";
CM_ SG_ 2566835198 SPN_High4 "3 most significant bits of SPN (most significant at bit 8) ";
CM_ SG_ 2566835198 SPN_High3 "3 most significant bits of SPN (most significant at bit 8) ";
CM_ SG_ 2566835198 SPN_High5 "3 most significant bits of SPN (most significant at bit 8) ";
CM_ SG_ 2566835198 SPN_High2 "3 most significant bits of SPN (most significant at bit 8) ";
CM_ SG_ 2566835198 SPN_High1 "3 most significant bits of SPN (most significant at bit 8) ";
CM_ SG_ 2566835198 SpnConversionMethod1 "If set to '0', the document is converted according to version 4 of the J1939-73 document (February 1996); otherwise, it is converted according to one of the three earlier versions.";
CM_ SG_ 2566835198 SpnConversionMethod5 "If set to '0', the document is converted according to version 4 of the J1939-73 document (February 1996); otherwise, it is converted according to one of the three earlier versions.";
CM_ SG_ 2566835198 SpnConversionMethod4 "If set to '0', the document is converted according to version 4 of the J1939-73 document (February 1996); otherwise, it is converted according to one of the three earlier versions.";
CM_ SG_ 2566835198 SpnConversionMethod3 "If set to '0', the document is converted according to version 4 of the J1939-73 document (February 1996); otherwise, it is converted according to one of the three earlier versions.";
CM_ SG_ 2566835198 SpnConversionMethod2 "If set to '0', the document is converted according to version 4 of the J1939-73 document (February 1996); otherwise, it is converted according to one of the three earlier versions.";
CM_ SG_ 2566835198 OccurenceCount5 "Contains the number of times a fault has been independently detected.";
CM_ SG_ 2566835198 OccurenceCount4 "Contains the number of times a fault has been independently detected.";
CM_ SG_ 2566835198 OccurenceCount3 "Contains the number of times a fault has been independently detected.";
CM_ SG_ 2566835198 OccurenceCount2 "Contains the number of times a fault has been independently detected.";
CM_ SG_ 2566835198 OccurenceCount1 "Contains the number of times a fault has been independently detected.";
CM_ SG_ 2566835198 FMI5 "The FMI defines the type of failure detected in the subsystem identified by an SPN.";
CM_ SG_ 2566835198 FMI4 "The FMI defines the type of failure detected in the subsystem identified by an SPN.";
CM_ SG_ 2566835198 FMI3 "The FMI defines the type of failure detected in the subsystem identified by an SPN.";
CM_ SG_ 2566835198 FMI2 "The FMI defines the type of failure detected in the subsystem identified by an SPN.";
CM_ SG_ 2566835198 FMI1 "The FMI defines the type of failure detected in the subsystem identified by an SPN.";
CM_ SG_ 2566835198 SPN5 "16 least significant bits of SPN";
CM_ SG_ 2566835198 SPN4 "16 least significant bits of SPN";
CM_ SG_ 2566835198 SPN3 "16 least significant bits of SPN";
CM_ SG_ 2566835198 SPN2 "16 least significant bits of SPN";
CM_ SG_ 2566835198 SPN1 "16 least significant bits of SPN";
CM_ BO_ 2566834942 "Active Diagnostic Trouble Codes
";
CM_ SG_ 2566834942 SPN_High4 "3 most significant bits of SPN (most significant at bit 8) ";
CM_ SG_ 2566834942 SPN_High3 "3 most significant bits of SPN (most significant at bit 8) ";
CM_ SG_ 2566834942 SPN_High5 "3 most significant bits of SPN (most significant at bit 8) ";
CM_ SG_ 2566834942 SPN_High2 "3 most significant bits of SPN (most significant at bit 8) ";
CM_ SG_ 2566834942 SPN_High1 "3 most significant bits of SPN (most significant at bit 8) ";
CM_ SG_ 2566834942 SpnConversionMethod1 "If set to '0', the document is converted according to version 4 of the J1939-73 document (February 1996); otherwise, it is converted according to one of the three earlier versions.";
CM_ SG_ 2566834942 SpnConversionMethod5 "If set to '0', the document is converted according to version 4 of the J1939-73 document (February 1996); otherwise, it is converted according to one of the three earlier versions.";
CM_ SG_ 2566834942 SpnConversionMethod4 "If set to '0', the document is converted according to version 4 of the J1939-73 document (February 1996); otherwise, it is converted according to one of the three earlier versions.";
CM_ SG_ 2566834942 SpnConversionMethod3 "If set to '0', the document is converted according to version 4 of the J1939-73 document (February 1996); otherwise, it is converted according to one of the three earlier versions.";
CM_ SG_ 2566834942 SpnConversionMethod2 "If set to '0', the document is converted according to version 4 of the J1939-73 document (February 1996); otherwise, it is converted according to one of the three earlier versions.";
CM_ SG_ 2566834942 OccurenceCount5 "Contains the number of times a fault has been independently detected.";
CM_ SG_ 2566834942 OccurenceCount4 "Contains the number of times a fault has been independently detected.";
CM_ SG_ 2566834942 OccurenceCount3 "Contains the number of times a fault has been independently detected.";
CM_ SG_ 2566834942 OccurenceCount2 "Contains the number of times a fault has been independently detected.";
CM_ SG_ 2566834942 OccurenceCount1 "Contains the number of times a fault has been independently detected.";
CM_ SG_ 2566834942 FMI5 "The FMI defines the type of failure detected in the subsystem identified by an SPN.";
CM_ SG_ 2566834942 FMI4 "The FMI defines the type of failure detected in the subsystem identified by an SPN.";
CM_ SG_ 2566834942 FMI3 "The FMI defines the type of failure detected in the subsystem identified by an SPN.";
CM_ SG_ 2566834942 FMI2 "The FMI defines the type of failure detected in the subsystem identified by an SPN.";
CM_ SG_ 2566834942 FMI1 "The FMI defines the type of failure detected in the subsystem identified by an SPN.";
CM_ SG_ 2566834942 SPN5 "16 least significant bits of SPN";
CM_ SG_ 2566834942 SPN4 "16 least significant bits of SPN";
CM_ SG_ 2566834942 SPN3 "16 least significant bits of SPN";
CM_ SG_ 2566834942 SPN2 "16 least significant bits of SPN";
CM_ SG_ 2566834942 SPN1 "16 least significant bits of SPN";
CM_ BO_ 2566655998 "Secondary or Front Hitch Roll and Pitch Sensitivity";
CM_ SG_ 2566655998 FrontHitchPitchSensitivity "Front hitch pitch sensitivity";
CM_ SG_ 2566655998 FrontHitchRollSensitivity "Front hitch roll sensitivity";
CM_ BO_ 2364604670 "Secondary or Front Hitch Roll and Pitch command";
CM_ SG_ 2364604670 FrontHitchPitchSensitivityCmd "Front hitch pitch sensitivity command";
CM_ SG_ 2364604670 FrontHitchPitchCommand "Front hitch pitch command";
CM_ SG_ 2364604670 FrontHitchRollSensitivityCommand "Front hitch roll sensitivity command";
CM_ SG_ 2364604670 FrontHitchRollCommand "Front hitch roll command";
CM_ BO_ 2364604414 "Secondary or Front Hitch Roll and Pitch";
CM_ SG_ 2364604414 FrontHitchPitchAngle "Front hitch pitch angle";
CM_ SG_ 2364604414 FrontHitchRollLimitStatus "Front hitch roll limit status";
CM_ SG_ 2364604414 FrontHitchRollExitCode "Front hitch roll exit/reason code";
CM_ SG_ 2364604414 FrontHitchRollAngle "Front hitch roll angle";
CM_ BO_ 2566655742 "Primary or Rear Hitch Roll and Pitch Sensitivity";
CM_ BO_ 2364605182 "Primary or Rear Hitch Roll and Pitch command";
CM_ SG_ 2364605182 RearHitchPitchSensitivityCmd "Rear hitch pitch sensitivity command";
CM_ SG_ 2364605182 RearHitchPitchCommand "Rear hitch pitch command";
CM_ SG_ 2364605182 RearHitchRollSensitivityCmd "Rear hitch roll sensitivity command";
CM_ SG_ 2364605182 RearHitchRollCommand "Rear hitch roll command";
CM_ SG_ 2364604926 RearHitchRollLimitStatus "Rear hitch pitch limit status";
CM_ SG_ 2364604926 RearHitchPitchAngle "Rear hitch pitch angle";
CM_ SG_ 2364604926 RearHitchRollAngle "Rear hitch roll angle";
CM_ SG_ 2365293822 OperatorStatusSequenceCounter "Operator Status Sequence Counter";
CM_ SG_ 2365293822 OperatorPresAwarChecksum "Operator Presence and Awareness Status Checksum";
CM_ SG_ 2365293822 OperatorAwarenessState "Operator Awareness state";
CM_ BO_ 2365293310 "Primary or Rear Hitch Yaw";
CM_ SG_ 2365293310 RearHitchYawLimitStat "Rear hitch yaw limit status";
CM_ SG_ 2365293310 RearHitchYawAngRefFr "Rear hitch yaw angle reference frame";
CM_ SG_ 2365293310 RearHitchYawExitCode "Rear hitch yaw exit/reason code";
CM_ SG_ 2365293310 RearHitchYawAngle "Measured yaw angle of rear hitch relative to the reference frame";
CM_ SG_ 2365293310 RearHitchYawAngActCtrlMod "Rear hitch yaw angle actual control mode";
CM_ BO_ 2364620542 "Secondary or Front Hitch Yaw command";
CM_ SG_ 2364620542 FrontHitchYawCommand "Front hitch yaw command. SPN 9719";
CM_ BO_ 2365293566 "Provides yaw information for the front hitch.";
CM_ SG_ 2365293566 FrontHitchYawLimitStatus "Parameter used to report the Tractor ECU's present limit status associated with the front hitch yaw commands";
CM_ SG_ 2365293566 FrontHitchYawAngleRefFrame "ption	This parameter is used to indicate the reference frame for the yaw angle of the front hitch";
CM_ SG_ 2365293566 FrontHitchYawAngleActualCtrlMode "Front hitch yaw angle actual control mode";
CM_ SG_ 2365293566 FrontHitchYawAngle "Measured yaw angle of front hitch relative to reference frame indicated by A.19.28 parameter";
CM_ BO_ 2566730494 "ECU diagnostic protocol";
CM_ SG_ 2566730494 DiagProtocolIdentification "Indicates the diagnostic protocols in addition to ISO 11783 that are supported by a control function";
CM_ BO_ 2625437438 "Request and report the supported and the actual Control Function Functionalities options and versions details";
CM_ BO_ 2364620798 "Primary or Rear Hitch Yaw command";
CM_ SG_ 2364620798 RearHitchYawCommand "Rear hitch yaw command";
CM_ BO_ 2621308670 "TIM client to TIM server (control status, v.2 and higher)";
BA_DEF_  "ISO11783_TIM_040_Security" STRING ;
BA_DEF_  "ISO11783_11_SpecVersion" STRING ;
BA_DEF_  "ISO11783_07_SpecVersion" STRING ;
BA_DEF_  "ISO11783_06_SpecVersion" STRING ;
BA_DEF_ SG_  "DDI" INT 0 65535;
BA_DEF_ BO_  "SingleFrame" INT 0 1;
BA_DEF_  "ProtocolType" STRING ;
BA_DEF_  "BusType" STRING ;
BA_DEF_  "ISO11783_TIM_023_Automation" STRING ;
BA_DEF_ BU_  "NmStationAddress" INT 0 255;
BA_DEF_ BO_  "VFrameFormat" ENUM  "StandardCAN","ExtendedCAN","reserved","J1939PG","vector_leerstring";
BA_DEF_ BO_  "GenMsgSendType" ENUM  "cyclic","NotUsed","IfActive","NotUsed","NotUsed","NotUsed","NotUsed","NotUsed","noMsgSendType","vector_leerstring";
BA_DEF_ BO_  "GenMsgCycleTime" INT 0 3600000;
BA_DEF_ BO_  "GenMsgRequestable" INT 0 1;
BA_DEF_ BO_  "GenMsgNrOfRepetition" INT 0 1000000;
BA_DEF_ BO_  "GenMsgCycleTimeFast" INT 0 3600000;
BA_DEF_ SG_  "GenSigInactiveValue" INT 0 0;
BA_DEF_ BO_  "GenMsgFastOnStart" INT 0 100000;
BA_DEF_ BO_  "GenMsgStartDelayTime" INT 0 100000;
BA_DEF_ BO_  "GenMsgILSupport" ENUM  "No","Yes";
BA_DEF_ BO_  "GenMsgDelayTime" INT 0 1000;
BA_DEF_ SG_  "SPN" INT 0 524287;
BA_DEF_  "DatabaseVersion" STRING ;
BA_DEF_ SG_  "GenSigSendType" ENUM  "Cyclic","OnWrite","OnWriteWithRepetition","OnChange","OnChangeWithRepetition","IfActive","IfActiveWithRepetition","NoSigSendType";
BA_DEF_ SG_  "SigType" ENUM  "Default","Range","RangeSigned","ASCII","Discrete","Control","ReferencePGN","DTC","StringDelimiter","StringLength","StringLengthControl","MessageCounter","MessageChecksum";
BA_DEF_  "ISO11783_12_SpecVersion" STRING ;
BA_DEF_  "ISO11783_13_SpecVersion" STRING ;
BA_DEF_ SG_  "GenSigStartValue" INT -2147483648 2147483647;
BA_DEF_ BU_  "ISO11783IOPVersion" ENUM  "0","1","2","3","4","5","6","7";
BA_DEF_ BU_  "ISO11783PDDVersion" ENUM  "0","1","2","3";
BA_DEF_ SG_  "GenSigILSupport" ENUM  "No","Yes";
BA_DEF_DEF_  "ISO11783_TIM_040_Security" "";
BA_DEF_DEF_  "ISO11783_11_SpecVersion" "";
BA_DEF_DEF_  "ISO11783_07_SpecVersion" "";
BA_DEF_DEF_  "ISO11783_06_SpecVersion" "";
BA_DEF_DEF_  "DDI" 0;
BA_DEF_DEF_  "SingleFrame" 1;
BA_DEF_DEF_  "ProtocolType" "";
BA_DEF_DEF_  "BusType" "";
BA_DEF_DEF_  "ISO11783_TIM_023_Automation" "";
BA_DEF_DEF_  "NmStationAddress" 254;
BA_DEF_DEF_  "VFrameFormat" "J1939PG";
BA_DEF_DEF_  "GenMsgSendType" "noMsgSendType";
BA_DEF_DEF_  "GenMsgCycleTime" 0;
BA_DEF_DEF_  "GenMsgRequestable" 1;
BA_DEF_DEF_  "GenMsgNrOfRepetition" 0;
BA_DEF_DEF_  "GenMsgCycleTimeFast" 0;
BA_DEF_DEF_  "GenSigInactiveValue" 0;
BA_DEF_DEF_  "GenMsgFastOnStart" 0;
BA_DEF_DEF_  "GenMsgStartDelayTime" 0;
BA_DEF_DEF_  "GenMsgILSupport" "Yes";
BA_DEF_DEF_  "GenMsgDelayTime" 0;
BA_DEF_DEF_  "SPN" 0;
BA_DEF_DEF_  "DatabaseVersion" "";
BA_DEF_DEF_  "GenSigSendType" "NoSigSendType";
BA_DEF_DEF_  "SigType" "Default";
BA_DEF_DEF_  "ISO11783_12_SpecVersion" "";
BA_DEF_DEF_  "ISO11783_13_SpecVersion" "";
BA_DEF_DEF_  "GenSigStartValue" 0;
BA_DEF_DEF_  "ISO11783IOPVersion" "6";
BA_DEF_DEF_  "ISO11783PDDVersion" "3";
BA_DEF_DEF_  "GenSigILSupport" "Yes";
BA_ "ISO11783_12_SpecVersion" "2018";
BA_ "DatabaseVersion" "19 SP3";
BA_ "ProtocolType" "ISO11783";
BA_ "ISO11783_06_SpecVersion" "2018";
BA_ "ISO11783_07_SpecVersion" "2014";
BA_ "ISO11783_11_SpecVersion" "2022";
BA_ "BusType" "CAN";
BA_ "ISO11783_13_SpecVersion" "2021";
BA_ "ISO11783_TIM_023_Automation" "2025 (4.00.001)";
BA_ "ISO11783_TIM_040_Security" "2025 (1.00.002)";
BA_ "GenMsgSendType" BO_ 2566655998 0;
BA_ "GenMsgDelayTime" BO_ 2566655998 100;
BA_ "GenMsgCycleTime" BO_ 2566655998 1000;
BA_ "GenMsgSendType" BO_ 2364604670 0;
BA_ "GenMsgCycleTime" BO_ 2364604670 100;
BA_ "GenMsgSendType" BO_ 2364604414 0;
BA_ "GenMsgCycleTime" BO_ 2364604414 100;
BA_ "GenMsgDelayTime" BO_ 2566655742 100;
BA_ "GenMsgCycleTime" BO_ 2566655742 1000;
BA_ "GenMsgSendType" BO_ 2566655742 0;
BA_ "GenMsgSendType" BO_ 2364605182 0;
BA_ "GenMsgCycleTime" BO_ 2364605182 100;
BA_ "GenMsgSendType" BO_ 2364604926 0;
BA_ "GenMsgCycleTime" BO_ 2364604926 100;
BA_ "GenMsgSendType" BO_ 2365293822 0;
BA_ "GenMsgDelayTime" BO_ 2365293822 200;
BA_ "GenMsgCycleTime" BO_ 2365293822 1000;
BA_ "GenMsgSendType" BO_ 2364620542 0;
BA_ "GenMsgCycleTime" BO_ 2364620542 100;
BA_ "GenMsgSendType" BO_ 2365293566 0;
BA_ "GenMsgCycleTime" BO_ 2365293566 100;
BA_ "SPN" SG_ 2566835198 SpnConversionMethod1 1706;
BA_ "SPN" SG_ 2566835198 SpnConversionMethod5 1706;
BA_ "SPN" SG_ 2566835198 SpnConversionMethod4 1706;
BA_ "SPN" SG_ 2566835198 SpnConversionMethod3 1706;
BA_ "SPN" SG_ 2566835198 SpnConversionMethod2 1706;
BA_ "SPN" SG_ 2566835198 OccurenceCount5 1216;
BA_ "SPN" SG_ 2566835198 OccurenceCount4 1216;
BA_ "SPN" SG_ 2566835198 OccurenceCount3 1216;
BA_ "SPN" SG_ 2566835198 OccurenceCount2 1216;
BA_ "SPN" SG_ 2566835198 OccurenceCount1 1216;
BA_ "SPN" SG_ 2566835198 FMI5 4149;
BA_ "SPN" SG_ 2566835198 FMI4 4149;
BA_ "SPN" SG_ 2566835198 FMI3 4149;
BA_ "SPN" SG_ 2566835198 FMI2 4149;
BA_ "SPN" SG_ 2566835198 FMI1 4149;
BA_ "SPN" SG_ 2566834942 SpnConversionMethod1 1706;
BA_ "SPN" SG_ 2566834942 SpnConversionMethod5 1706;
BA_ "SPN" SG_ 2566834942 SpnConversionMethod4 1706;
BA_ "SPN" SG_ 2566834942 SpnConversionMethod3 1706;
BA_ "SPN" SG_ 2566834942 SpnConversionMethod2 1706;
BA_ "SPN" SG_ 2566834942 OccurenceCount5 1216;
BA_ "SPN" SG_ 2566834942 OccurenceCount4 1216;
BA_ "SPN" SG_ 2566834942 OccurenceCount3 1216;
BA_ "SPN" SG_ 2566834942 OccurenceCount2 1216;
BA_ "SPN" SG_ 2566834942 OccurenceCount1 1216;
BA_ "SPN" SG_ 2566834942 FMI5 4149;
BA_ "SPN" SG_ 2566834942 FMI4 4149;
BA_ "SPN" SG_ 2566834942 FMI3 4149;
BA_ "SPN" SG_ 2566834942 FMI2 4149;
BA_ "SPN" SG_ 2566834942 FMI1 4149;
BA_ "GenSigStartValue" SG_ 2364604670 FrontHitchPitchCommand 32000;
BA_ "GenSigStartValue" SG_ 2364604670 FrontHitchRollCommand 32000;
BA_ "GenSigStartValue" SG_ 2364604414 FrontHitchPitchAngle 32000;
BA_ "GenSigStartValue" SG_ 2364604414 FrontHitchRollAngle 32000;
BA_ "GenSigStartValue" SG_ 2364605182 RearHitchPitchCommand 32000;
BA_ "GenSigStartValue" SG_ 2364605182 RearHitchRollCommand 32000;
BA_ "GenSigStartValue" SG_ 2364604926 RearHitchPitchAngle 32000;
BA_ "GenSigStartValue" SG_ 2364604926 RearHitchRollAngle 32000;
BA_ "GenSigStartValue" SG_ 2365293310 RearHitchYawAngle 25600;
BA_ "GenSigStartValue" SG_ 2364620542 FrontHitchYawCommand 25600;
BA_ "GenSigStartValue" SG_ 2365293566 FrontHitchYawAngle 25600;
BA_ "GenSigStartValue" SG_ 2364620798 RearHitchYawCommand 25600;
BA_ "SigType" SG_ 2621308670 VSpeedIncAggressivenessReq_VS 1;
BA_ "SPN" SG_ 2621308670 VSpeedIncAggressivenessReq_VS 8815;
BA_ "SPN" SG_ 2621308670 VSpeedDecAggressivenessReq_VS 8815;
BA_ "SigType" SG_ 2621308670 VSpeedDecAggressivenessReq_VS 1;
BA_ "SigType" SG_ 2621308670 RSpeedIncAggressivenessReq_RPTO 1;
BA_ "SigType" SG_ 2621308670 RSpeedIncAggressivenessReq_FPTO 1;
BA_ "SigType" SG_ 2621308670 RSpeedDecAggressivenessReq_RPTO 1;
BA_ "SigType" SG_ 2621308670 RSpeedDecAggressivenessReq_FPTO 1;
BA_ "SPN" SG_ 2621308670 PositionIncAggressivenessReq_RTL 23590;
BA_ "SPN" SG_ 2621308670 PositionIncAggressivenessReq_RH 8814;
BA_ "SigType" SG_ 2621308670 PositionIncAggressivenessReq_RH 1;
BA_ "SPN" SG_ 2621308670 PositionIncAggressivenessReq_FTL 23589;
BA_ "SPN" SG_ 2621308670 PositionIncAggressivenessReq_FH 8813;
BA_ "SigType" SG_ 2621308670 PositionIncAggressivenessReq_FH 1;
BA_ "SPN" SG_ 2621308670 PositionDecAggressivenessReq_RTL 23590;
BA_ "SPN" SG_ 2621308670 PositionDecAggressivenessReq_RH 8814;
BA_ "SigType" SG_ 2621308670 PositionDecAggressivenessReq_RH 1;
BA_ "SPN" SG_ 2621308670 PositionDecAggressivenessReq_FTL 23589;
BA_ "SPN" SG_ 2621308670 PositionDecAggressivenessReq_FH 8813;
BA_ "SigType" SG_ 2621308670 PositionDecAggressivenessReq_FH 1;
BA_ "SigType" SG_ 2621308670 FlowIncAggressivenessReq_AV32 1;
BA_ "SigType" SG_ 2621308670 FlowIncAggressivenessReq_AV31 1;
BA_ "SigType" SG_ 2621308670 FlowIncAggressivenessReq_AV30 1;
BA_ "SigType" SG_ 2621308670 FlowIncAggressivenessReq_AV29 1;
BA_ "SigType" SG_ 2621308670 FlowIncAggressivenessReq_AV28 1;
BA_ "SigType" SG_ 2621308670 FlowIncAggressivenessReq_AV27 1;
BA_ "SigType" SG_ 2621308670 FlowIncAggressivenessReq_AV26 1;
BA_ "SigType" SG_ 2621308670 FlowIncAggressivenessReq_AV25 1;
BA_ "SigType" SG_ 2621308670 FlowIncAggressivenessReq_AV24 1;
BA_ "SigType" SG_ 2621308670 FlowIncAggressivenessReq_AV23 1;
BA_ "SigType" SG_ 2621308670 FlowIncAggressivenessReq_AV22 1;
BA_ "SigType" SG_ 2621308670 FlowIncAggressivenessReq_AV21 1;
BA_ "SigType" SG_ 2621308670 FlowIncAggressivenessReq_AV20 1;
BA_ "SigType" SG_ 2621308670 FlowIncAggressivenessReq_AV19 1;
BA_ "SigType" SG_ 2621308670 FlowIncAggressivenessReq_AV18 1;
BA_ "SigType" SG_ 2621308670 FlowIncAggressivenessReq_AV17 1;
BA_ "SigType" SG_ 2621308670 FlowIncAggressivenessReq_AV16 1;
BA_ "SigType" SG_ 2621308670 FlowIncAggressivenessReq_AV15 1;
BA_ "SigType" SG_ 2621308670 FlowIncAggressivenessReq_AV14 1;
BA_ "SigType" SG_ 2621308670 FlowIncAggressivenessReq_AV13 1;
BA_ "SigType" SG_ 2621308670 FlowIncAggressivenessReq_AV12 1;
BA_ "SigType" SG_ 2621308670 FlowIncAggressivenessReq_AV11 1;
BA_ "SigType" SG_ 2621308670 FlowIncAggressivenessReq_AV10 1;
BA_ "SigType" SG_ 2621308670 FlowIncAggressivenessReq_AV09 1;
BA_ "SigType" SG_ 2621308670 FlowIncAggressivenessReq_AV08 1;
BA_ "SigType" SG_ 2621308670 FlowIncAggressivenessReq_AV07 1;
BA_ "SigType" SG_ 2621308670 FlowIncAggressivenessReq_AV06 1;
BA_ "SigType" SG_ 2621308670 FlowIncAggressivenessReq_AV05 1;
BA_ "SigType" SG_ 2621308670 FlowIncAggressivenessReq_AV04 1;
BA_ "SigType" SG_ 2621308670 FlowIncAggressivenessReq_AV03 1;
BA_ "SigType" SG_ 2621308670 FlowIncAggressivenessReq_AV02 1;
BA_ "SigType" SG_ 2621308670 FlowIncAggressivenessReq_AV01 1;
BA_ "SigType" SG_ 2621308670 FlowDecAggressivenessReq_AV32 1;
BA_ "SigType" SG_ 2621308670 FlowDecAggressivenessReq_AV31 1;
BA_ "SigType" SG_ 2621308670 FlowDecAggressivenessReq_AV30 1;
BA_ "SigType" SG_ 2621308670 FlowDecAggressivenessReq_AV29 1;
BA_ "SigType" SG_ 2621308670 FlowDecAggressivenessReq_AV28 1;
BA_ "SigType" SG_ 2621308670 FlowDecAggressivenessReq_AV27 1;
BA_ "SigType" SG_ 2621308670 FlowDecAggressivenessReq_AV26 1;
BA_ "SigType" SG_ 2621308670 FlowDecAggressivenessReq_AV25 1;
BA_ "SigType" SG_ 2621308670 FlowDecAggressivenessReq_AV24 1;
BA_ "SigType" SG_ 2621308670 FlowDecAggressivenessReq_AV23 1;
BA_ "SigType" SG_ 2621308670 FlowDecAggressivenessReq_AV22 1;
BA_ "SigType" SG_ 2621308670 FlowDecAggressivenessReq_AV21 1;
BA_ "SigType" SG_ 2621308670 FlowDecAggressivenessReq_AV20 1;
BA_ "SigType" SG_ 2621308670 FlowDecAggressivenessReq_AV19 1;
BA_ "SigType" SG_ 2621308670 FlowDecAggressivenessReq_AV18 1;
BA_ "SigType" SG_ 2621308670 FlowDecAggressivenessReq_AV17 1;
BA_ "SigType" SG_ 2621308670 FlowDecAggressivenessReq_AV16 1;
BA_ "SigType" SG_ 2621308670 FlowDecAggressivenessReq_AV15 1;
BA_ "SigType" SG_ 2621308670 FlowDecAggressivenessReq_AV14 1;
BA_ "SigType" SG_ 2621308670 FlowDecAggressivenessReq_AV13 1;
BA_ "SigType" SG_ 2621308670 FlowDecAggressivenessReq_AV12 1;
BA_ "SigType" SG_ 2621308670 FlowDecAggressivenessReq_AV11 1;
BA_ "SigType" SG_ 2621308670 FlowDecAggressivenessReq_AV10 1;
BA_ "SigType" SG_ 2621308670 FlowDecAggressivenessReq_AV09 1;
BA_ "SigType" SG_ 2621308670 FlowDecAggressivenessReq_AV08 1;
BA_ "SigType" SG_ 2621308670 FlowDecAggressivenessReq_AV07 1;
BA_ "SigType" SG_ 2621308670 FlowDecAggressivenessReq_AV06 1;
BA_ "SigType" SG_ 2621308670 FlowDecAggressivenessReq_AV05 1;
BA_ "SigType" SG_ 2621308670 FlowDecAggressivenessReq_AV04 1;
BA_ "SigType" SG_ 2621308670 FlowDecAggressivenessReq_AV03 1;
BA_ "SigType" SG_ 2621308670 FlowDecAggressivenessReq_AV02 1;
BA_ "SigType" SG_ 2621308670 FlowDecAggressivenessReq_AV01 1;
BA_ "SPN" SG_ 2621308670 CurvatureAggressivenessReq_EG 8816;
BA_ "SigType" SG_ 2621308670 CurvatureAggressivenessReq_EG 1;
BA_ "SPN" SG_ 2621308670 PositionRequest_RTL 23590;
BA_ "SPN" SG_ 2621308670 PositionRequest_FTL 23589;
BA_ "SPN" SG_ 2621308670 ControlMode1_VS 23581;
BA_ "SPN" SG_ 2621308670 ControlMode1_RTL 23581;
BA_ "SPN" SG_ 2621308670 ControlMode1_FTL 23581;
BA_ "SPN" SG_ 2621308670 NumOfControlModes_VS 23875;
BA_ "SPN" SG_ 2621308670 NumOfControlModes_RTL 23875;
BA_ "SPN" SG_ 2621308670 NumOfControlModes_FTL 23875;
BA_ "SPN" SG_ 2621308670 NumOfBytes_CM1_VS 23876;
BA_ "SPN" SG_ 2621308670 NumOfBytes_CM1_RTL 23876;
BA_ "SPN" SG_ 2621308670 NumOfBytes_CM1_FTL 23876;
BA_ "SPN" SG_ 2621308670 FlowRequest_AV32 8810;
BA_ "SigType" SG_ 2621308670 FlowRequest_AV32 1;
BA_ "GenSigStartValue" SG_ 2621308670 FlowRequest_AV32 32128;
BA_ "SigType" SG_ 2621308670 FlowRequest_AV31 1;
BA_ "GenSigStartValue" SG_ 2621308670 FlowRequest_AV31 32128;
BA_ "SPN" SG_ 2621308670 FlowRequest_AV31 8809;
BA_ "SigType" SG_ 2621308670 FlowRequest_AV30 1;
BA_ "GenSigStartValue" SG_ 2621308670 FlowRequest_AV30 32128;
BA_ "SPN" SG_ 2621308670 FlowRequest_AV30 8808;
BA_ "SigType" SG_ 2621308670 FlowRequest_AV29 1;
BA_ "GenSigStartValue" SG_ 2621308670 FlowRequest_AV29 32128;
BA_ "SPN" SG_ 2621308670 FlowRequest_AV29 8807;
BA_ "SigType" SG_ 2621308670 FlowRequest_AV28 1;
BA_ "GenSigStartValue" SG_ 2621308670 FlowRequest_AV28 32128;
BA_ "SPN" SG_ 2621308670 FlowRequest_AV28 8806;
BA_ "SigType" SG_ 2621308670 FlowRequest_AV27 1;
BA_ "GenSigStartValue" SG_ 2621308670 FlowRequest_AV27 32128;
BA_ "SPN" SG_ 2621308670 FlowRequest_AV27 8805;
BA_ "SigType" SG_ 2621308670 FlowRequest_AV26 1;
BA_ "GenSigStartValue" SG_ 2621308670 FlowRequest_AV26 32128;
BA_ "SPN" SG_ 2621308670 FlowRequest_AV26 8804;
BA_ "SigType" SG_ 2621308670 FlowRequest_AV25 1;
BA_ "GenSigStartValue" SG_ 2621308670 FlowRequest_AV25 32128;
BA_ "SPN" SG_ 2621308670 FlowRequest_AV25 8803;
BA_ "SigType" SG_ 2621308670 FlowRequest_AV24 1;
BA_ "GenSigStartValue" SG_ 2621308670 FlowRequest_AV24 32128;
BA_ "SPN" SG_ 2621308670 FlowRequest_AV24 8802;
BA_ "SigType" SG_ 2621308670 FlowRequest_AV23 1;
BA_ "GenSigStartValue" SG_ 2621308670 FlowRequest_AV23 32128;
BA_ "SPN" SG_ 2621308670 FlowRequest_AV23 8801;
BA_ "SigType" SG_ 2621308670 FlowRequest_AV22 1;
BA_ "GenSigStartValue" SG_ 2621308670 FlowRequest_AV22 32128;
BA_ "SPN" SG_ 2621308670 FlowRequest_AV22 8800;
BA_ "SigType" SG_ 2621308670 FlowRequest_AV21 1;
BA_ "GenSigStartValue" SG_ 2621308670 FlowRequest_AV21 32128;
BA_ "SPN" SG_ 2621308670 FlowRequest_AV21 8799;
BA_ "SigType" SG_ 2621308670 FlowRequest_AV20 1;
BA_ "GenSigStartValue" SG_ 2621308670 FlowRequest_AV20 32128;
BA_ "SPN" SG_ 2621308670 FlowRequest_AV20 8798;
BA_ "SigType" SG_ 2621308670 FlowRequest_AV19 1;
BA_ "GenSigStartValue" SG_ 2621308670 FlowRequest_AV19 32128;
BA_ "SPN" SG_ 2621308670 FlowRequest_AV19 8797;
BA_ "SigType" SG_ 2621308670 FlowRequest_AV18 1;
BA_ "GenSigStartValue" SG_ 2621308670 FlowRequest_AV18 32128;
BA_ "SPN" SG_ 2621308670 FlowRequest_AV18 8796;
BA_ "SigType" SG_ 2621308670 FlowRequest_AV17 1;
BA_ "GenSigStartValue" SG_ 2621308670 FlowRequest_AV17 32128;
BA_ "SPN" SG_ 2621308670 FlowRequest_AV17 8795;
BA_ "SigType" SG_ 2621308670 FlowRequest_AV16 1;
BA_ "GenSigStartValue" SG_ 2621308670 FlowRequest_AV16 32128;
BA_ "SPN" SG_ 2621308670 FlowRequest_AV16 8794;
BA_ "SigType" SG_ 2621308670 FlowRequest_AV15 1;
BA_ "GenSigStartValue" SG_ 2621308670 FlowRequest_AV15 32128;
BA_ "SPN" SG_ 2621308670 FlowRequest_AV15 8793;
BA_ "SigType" SG_ 2621308670 FlowRequest_AV14 1;
BA_ "GenSigStartValue" SG_ 2621308670 FlowRequest_AV14 32128;
BA_ "SPN" SG_ 2621308670 FlowRequest_AV14 8792;
BA_ "SigType" SG_ 2621308670 FlowRequest_AV13 1;
BA_ "GenSigStartValue" SG_ 2621308670 FlowRequest_AV13 32128;
BA_ "SPN" SG_ 2621308670 FlowRequest_AV13 8791;
BA_ "SigType" SG_ 2621308670 FlowRequest_AV12 1;
BA_ "GenSigStartValue" SG_ 2621308670 FlowRequest_AV12 32128;
BA_ "SPN" SG_ 2621308670 FlowRequest_AV12 8790;
BA_ "SigType" SG_ 2621308670 FlowRequest_AV11 1;
BA_ "GenSigStartValue" SG_ 2621308670 FlowRequest_AV11 32128;
BA_ "SPN" SG_ 2621308670 FlowRequest_AV11 8789;
BA_ "SigType" SG_ 2621308670 FlowRequest_AV10 1;
BA_ "GenSigStartValue" SG_ 2621308670 FlowRequest_AV10 32128;
BA_ "SPN" SG_ 2621308670 FlowRequest_AV10 8788;
BA_ "SigType" SG_ 2621308670 FlowRequest_AV09 1;
BA_ "GenSigStartValue" SG_ 2621308670 FlowRequest_AV09 32128;
BA_ "SPN" SG_ 2621308670 FlowRequest_AV09 8787;
BA_ "SigType" SG_ 2621308670 FlowRequest_AV08 1;
BA_ "GenSigStartValue" SG_ 2621308670 FlowRequest_AV08 32128;
BA_ "SPN" SG_ 2621308670 FlowRequest_AV08 8786;
BA_ "SigType" SG_ 2621308670 FlowRequest_AV07 1;
BA_ "GenSigStartValue" SG_ 2621308670 FlowRequest_AV07 32128;
BA_ "SPN" SG_ 2621308670 FlowRequest_AV07 8785;
BA_ "SigType" SG_ 2621308670 FlowRequest_AV06 1;
BA_ "GenSigStartValue" SG_ 2621308670 FlowRequest_AV06 32128;
BA_ "SPN" SG_ 2621308670 FlowRequest_AV06 8784;
BA_ "SigType" SG_ 2621308670 FlowRequest_AV05 1;
BA_ "GenSigStartValue" SG_ 2621308670 FlowRequest_AV05 32128;
BA_ "SPN" SG_ 2621308670 FlowRequest_AV05 8783;
BA_ "SigType" SG_ 2621308670 FlowRequest_AV04 1;
BA_ "GenSigStartValue" SG_ 2621308670 FlowRequest_AV04 32128;
BA_ "SPN" SG_ 2621308670 FlowRequest_AV04 8782;
BA_ "SigType" SG_ 2621308670 FlowRequest_AV03 1;
BA_ "GenSigStartValue" SG_ 2621308670 FlowRequest_AV03 32128;
BA_ "SPN" SG_ 2621308670 FlowRequest_AV03 8781;
BA_ "SigType" SG_ 2621308670 FlowRequest_AV02 1;
BA_ "GenSigStartValue" SG_ 2621308670 FlowRequest_AV02 32128;
BA_ "SPN" SG_ 2621308670 FlowRequest_AV02 8780;
BA_ "SigType" SG_ 2621308670 PositionRequest_RH 1;
BA_ "SPN" SG_ 2621308670 PositionRequest_RH 8814;
BA_ "SigType" SG_ 2621308670 OutputShaftSpeedRequest_RPTO 1;
BA_ "GenSigStartValue" SG_ 2621308670 OutputShaftSpeedRequest_RPTO 32128;
BA_ "SPN" SG_ 2621308670 OutputShaftSpeedRequest_RPTO 8812;
BA_ "SigType" SG_ 2621308670 CurvatureRequest_EG 1;
BA_ "GenSigStartValue" SG_ 2621308670 CurvatureRequest_EG 32128;
BA_ "SPN" SG_ 2621308670 CurvatureRequest_EG 8816;
BA_ "SigType" SG_ 2621308670 VehicleSpeedRequest_VS 1;
BA_ "GenSigStartValue" SG_ 2621308670 VehicleSpeedRequest_VS 32128;
BA_ "SPN" SG_ 2621308670 VehicleSpeedRequest_VS 8815;
BA_ "SigType" SG_ 2621308670 PositionRequest_FH 1;
BA_ "SPN" SG_ 2621308670 PositionRequest_FH 8813;
BA_ "SigType" SG_ 2621308670 OutputShaftSpeedRequest_FPTO 1;
BA_ "GenSigStartValue" SG_ 2621308670 OutputShaftSpeedRequest_FPTO 32128;
BA_ "SPN" SG_ 2621308670 OutputShaftSpeedRequest_FPTO 8811;
BA_ "SigType" SG_ 2621308670 FlowRequest_AV01 1;
BA_ "GenSigStartValue" SG_ 2621308670 FlowRequest_AV01 32128;
BA_ "SPN" SG_ 2621308670 FlowRequest_AV01 8779;
VAL_ 2566835198 FMI5 24 "Assurance Data Error" 23 "Request DM60 for more info" 22 "Special Instructions #2 " 21 "Data drifted low" 20 "Data drifted high" 31 "Condition exists" 19 "Received network data in error" 18 "Below normal (moderately severe)" 17 "Below normal (least severe)" 16 "Above normal (moderately severe)" 15 "Above normal (least severe)" 14 "Special intstructions" 13 "Out of calibration" 12 "Bad intelligent device" 11 "Root cause not known" 10 "Abnormal rate of change" 9 "Abnormal update rate" 8 "Abnormal frequency" 7 "Mechanical system not responding" 6 "Current above normal" 5 "Current below normal" 4 "Voltage below normal" 3 "Voltage above normal" 2 "Data erratic" 1 "Below normal (most severe)" 0 "Above normal (most severe)" ;
VAL_ 2566835198 FMI4 24 "Assurance Data Error" 23 "Request DM60 for more info" 22 "Special Instructions #2 " 21 "Data drifted low" 20 "Data drifted high" 31 "Condition exists" 19 "Received network data in error" 18 "Below normal (moderately severe)" 17 "Below normal (least severe)" 16 "Above normal (moderately severe)" 15 "Above normal (least severe)" 14 "Special intstructions" 13 "Out of calibration" 12 "Bad intelligent device" 11 "Root cause not known" 10 "Abnormal rate of change" 9 "Abnormal update rate" 8 "Abnormal frequency" 7 "Mechanical system not responding" 6 "Current above normal" 5 "Current below normal" 4 "Voltage below normal" 3 "Voltage above normal" 2 "Data erratic" 1 "Below normal (most severe)" 0 "Above normal (most severe)" ;
VAL_ 2566835198 FMI3 24 "Assurance Data Error" 23 "Request DM60 for more info" 22 "Special Instructions #2 " 21 "Data drifted low" 20 "Data drifted high" 31 "Condition exists" 19 "Received network data in error" 18 "Below normal (moderately severe)" 17 "Below normal (least severe)" 16 "Above normal (moderately severe)" 15 "Above normal (least severe)" 14 "Special intstructions" 13 "Out of calibration" 12 "Bad intelligent device" 11 "Root cause not known" 10 "Abnormal rate of change" 9 "Abnormal update rate" 8 "Abnormal frequency" 7 "Mechanical system not responding" 6 "Current above normal" 5 "Current below normal" 4 "Voltage below normal" 3 "Voltage above normal" 2 "Data erratic" 1 "Below normal (most severe)" 0 "Above normal (most severe)" ;
VAL_ 2566835198 FMI2 24 "Assurance Data Error" 23 "Request DM60 for more info" 22 "Special Instructions #2 " 21 "Data drifted low" 20 "Data drifted high" 31 "Condition exists" 19 "Received network data in error" 18 "Below normal (moderately severe)" 17 "Below normal (least severe)" 16 "Above normal (moderately severe)" 15 "Above normal (least severe)" 14 "Special intstructions" 13 "Out of calibration" 12 "Bad intelligent device" 11 "Root cause not known" 10 "Abnormal rate of change" 9 "Abnormal update rate" 8 "Abnormal frequency" 7 "Mechanical system not responding" 6 "Current above normal" 5 "Current below normal" 4 "Voltage below normal" 3 "Voltage above normal" 2 "Data erratic" 1 "Below normal (most severe)" 0 "Above normal (most severe)" ;
VAL_ 2566835198 FMI1 24 "Assurance Data Error" 23 "Request DM60 for more info" 22 "Special Instructions #2 " 21 "Data drifted low" 20 "Data drifted high" 31 "Condition exists" 19 "Received network data in error" 18 "Below normal (moderately severe)" 17 "Below normal (least severe)" 16 "Above normal (moderately severe)" 15 "Above normal (least severe)" 14 "Special intstructions" 13 "Out of calibration" 12 "Bad intelligent device" 11 "Root cause not known" 10 "Abnormal rate of change" 9 "Abnormal update rate" 8 "Abnormal frequency" 7 "Mechanical system not responding" 6 "Current above normal" 5 "Current below normal" 4 "Voltage below normal" 3 "Voltage above normal" 2 "Data erratic" 1 "Below normal (most severe)" 0 "Above normal (most severe)" ;
VAL_ 2566834942 FMI5 24 "Assurance Data Error" 23 "Request DM60 for more info" 22 "Special Instructions #2 " 21 "Data drifted low" 20 "Data drifted high" 31 "Condition exists" 19 "Received network data in error" 18 "Below normal (moderately severe)" 17 "Below normal (least severe)" 16 "Above normal (moderately severe)" 15 "Above normal (least severe)" 14 "Special intstructions" 13 "Out of calibration" 12 "Bad intelligent device" 11 "Root cause not known" 10 "Abnormal rate of change" 9 "Abnormal update rate" 8 "Abnormal frequency" 7 "Mechanical system not responding" 6 "Current above normal" 5 "Current below normal" 4 "Voltage below normal" 3 "Voltage above normal" 2 "Data erratic" 1 "Below normal (most severe)" 0 "Above normal (most severe)" ;
VAL_ 2566834942 FMI4 24 "Assurance Data Error" 23 "Request DM60 for more info" 22 "Special Instructions #2 " 21 "Data drifted low" 20 "Data drifted high" 31 "Condition exists" 19 "Received network data in error" 18 "Below normal (moderately severe)" 17 "Below normal (least severe)" 16 "Above normal (moderately severe)" 15 "Above normal (least severe)" 14 "Special intstructions" 13 "Out of calibration" 12 "Bad intelligent device" 11 "Root cause not known" 10 "Abnormal rate of change" 9 "Abnormal update rate" 8 "Abnormal frequency" 7 "Mechanical system not responding" 6 "Current above normal" 5 "Current below normal" 4 "Voltage below normal" 3 "Voltage above normal" 2 "Data erratic" 1 "Below normal (most severe)" 0 "Above normal (most severe)" ;
VAL_ 2566834942 FMI3 24 "Assurance Data Error" 23 "Request DM60 for more info" 22 "Special Instructions #2 " 21 "Data drifted low" 20 "Data drifted high" 31 "Condition exists" 19 "Received network data in error" 18 "Below normal (moderately severe)" 17 "Below normal (least severe)" 16 "Above normal (moderately severe)" 15 "Above normal (least severe)" 14 "Special intstructions" 13 "Out of calibration" 12 "Bad intelligent device" 11 "Root cause not known" 10 "Abnormal rate of change" 9 "Abnormal update rate" 8 "Abnormal frequency" 7 "Mechanical system not responding" 6 "Current above normal" 5 "Current below normal" 4 "Voltage below normal" 3 "Voltage above normal" 2 "Data erratic" 1 "Below normal (most severe)" 0 "Above normal (most severe)" ;
VAL_ 2566834942 FMI2 24 "Assurance Data Error" 23 "Request DM60 for more info" 22 "Special Instructions #2 " 21 "Data drifted low" 20 "Data drifted high" 31 "Condition exists" 19 "Received network data in error" 18 "Below normal (moderately severe)" 17 "Below normal (least severe)" 16 "Above normal (moderately severe)" 15 "Above normal (least severe)" 14 "Special intstructions" 13 "Out of calibration" 12 "Bad intelligent device" 11 "Root cause not known" 10 "Abnormal rate of change" 9 "Abnormal update rate" 8 "Abnormal frequency" 7 "Mechanical system not responding" 6 "Current above normal" 5 "Current below normal" 4 "Voltage below normal" 3 "Voltage above normal" 2 "Data erratic" 1 "Below normal (most severe)" 0 "Above normal (most severe)" ;
VAL_ 2566834942 FMI1 24 "Assurance Data Error" 23 "Request DM60 for more info" 22 "Special Instructions #2 " 21 "Data drifted low" 20 "Data drifted high" 31 "Condition exists" 19 "Received network data in error" 18 "Below normal (moderately severe)" 17 "Below normal (least severe)" 16 "Above normal (moderately severe)" 15 "Above normal (least severe)" 14 "Special intstructions" 13 "Out of calibration" 12 "Bad intelligent device" 11 "Root cause not known" 10 "Abnormal rate of change" 9 "Abnormal update rate" 8 "Abnormal frequency" 7 "Mechanical system not responding" 6 "Current above normal" 5 "Current below normal" 4 "Voltage below normal" 3 "Voltage above normal" 2 "Data erratic" 1 "Below normal (most severe)" 0 "Above normal (most severe)" ;
VAL_ 2364604414 FrontHitchPitchLimitStatus 7 "Not available" 6 "Non-recoverable fault" 3 "Limited low" 2 "Limited high" 1 "Operator limited" 0 "Not limited" ;
VAL_ 2364604414 FrontHitchPitchExitCode 21 "Hitch locked out" 20 "Hydraulic oil level too low" 63 "Description for the value '0xE'" 62 "Description for the value '0xD'" 9 "Func fault" 8 "Operator ctrl fault" 7 "Func not calibrated" 6 "Remote cmd out of range" 5 "Remote cmd timeout" 4 "Operator ctrl not in valid pos" 3 "Operator override of func" 2 "Implement released ctrl of func" 1 "Required level of OP presence" 0 "No reason" ;
VAL_ 2364604414 FrontHitchRollLimitStatus 7 "Not available" 6 "Non-revocerable fault" 3 "Limited low" 2 "Limited high" 1 "Operator limited" 0 "Not limited" ;
VAL_ 2364604414 FrontHitchRollExitCode 63 "Not available" 62 "Error" 21 "Hitch locked out" 20 "Hydraulic oil level too low" 9 "Func fault" 8 "Operator ctrl fault" 7 "Func not calibrated" 6 "Remote cmd out of range" 5 "Remote cmd timeout" 4 "Operator ctrl not in valid pos" 3 "Operator override of func" 2 "Implement released ctrl of func" 1 "Required level of OP presence" 0 "No reason, all clear" ;
VAL_ 2364604926 RearHitchRollLimitStatus 7 "Not available" 6 "Non-recoverable fault" 3 "Limited low" 2 "Limited high" 1 "Operator limited" 0 "Not limited" ;
VAL_ 2364604926 RearHitchPitchExitCode 21 "Hitch locked out" 20 "Hydraulic oil level too low" 63 "Description for the value '0xE'" 62 "Description for the value '0xD'" 9 "Func fault" 8 "Operator ctrl fault" 7 "Func not calibrated" 6 "Remote cmd out of range" 5 "Remote cmd timeout" 4 "Operator ctrl not in valid pos" 3 "Operator override of func" 2 "Implement released ctrl of func" 1 "Required level of OP presence" 0 "No reason" ;
VAL_ 2364604926 RearHitchPitchLimitStatus 7 "Not available" 6 "Non-recoverable fault" 3 "Limited low" 2 "Limited high" 1 "Operator limited" 0 "Not limited" ;
VAL_ 2364604926 RearHitchRollExitCode 63 "Description for the value '0xD'" 62 "Error" 21 "Hitch locked out" 20 "Hydraulic oil level too low" 9 "Func fault" 8 "Operator ctrl fault" 7 "Func not calibrated" 6 "Remote cmd out of range" 5 "Remote cmd timeout" 4 "Operator ctrl not in valid pos" 3 "Operator override of func" 2 "Implement released ctrl of func" 1 "Required level of OP presence" 0 "No reason, all clear" ;
VAL_ 2365293822 OperatorStatusSequenceCounter 255 "Description for the value '0x3'" 254 "Error condition on sender" 251 "Reset sequence counter" ;
VAL_ 2365293822 OperatorPresenceState 3 "Not available" 2 "Error indication" 1 "Operator present" 0 "Operator not present" ;
VAL_ 2365293822 OperatorAwarenessState 3 "Not available" 2 "Error indication" 1 "Operator aware" 0 "Operator not aware" ;
VAL_ 2365293310 RearHitchYawLimitStat 7 "Not available" 6 "Non-recoverable fault" 3 "Limited Low" 2 "Limited High" 1 "Operator limited" 0 "Not limited" ;
VAL_ 2365293310 RearHitchYawAngRefFr 15 "Not available" 14 "Nonrecoverable fault" 2 "Direction of travel" 1 "Body of the hitch" 0 "Main body of the machine" ;
VAL_ 2365293310 RearHitchYawExitCode 63 "Description for the value '0xE'" 62 "Error" 21 "Hitch locked out" 20 "Hydraulic oil level too low" 9 "Fct. fault" 8 "Operator ctrl. fault" 7 "Fct. not calibrated" 6 "Remote cmd. out of range" 5 "Remote cmd. timeout" 4 "Operator ctrl not in valid pos." 3 "Operator override of fct." 2 "Impl. released ctrl. of fct." 1 "Required operator presence" 0 "No reason" ;
VAL_ 2365293310 RearHitchYawAngActCtrlMod 15 "Not available" 14 "Error indication" 5 "Auto ctrl: position control" 4 "Auto ctrl: basic curvature" 3 "Auto ctrl: steering wheels" 2 "Floating mode" 1 "Direct hydraulic valve control" 0 "Disabled, yaw angle locked" ;
VAL_ 2365293566 FrontHitchYawLimitStatus 7 "Not available" 6 "Nonrecoverable fault" 3 "Limited low" 2 "Limited high" 1 "Operator limited/controlled" 0 "Not limited" ;
VAL_ 2365293566 FrontHitchYawExitCode 63 "Description for the value '0xF'" 62 "Description for the value '0xE'" 21 "Hitch locked out" 20 "Hydraulic oil level too low" 9 "Fct. fault" 8 "Operator ctrl. fault" 7 "Fct. not calibrated" 6 "Remote cmd. out of range" 5 "Remote cmd. timeout" 4 "Operator ctrl. not in valid pos." 3 "Operator override of fct." 2 "Implement release ctrl. of fct." 1 "Required operator presence" 0 "No reason/all clear" ;
VAL_ 2365293566 FrontHitchYawAngleRefFrame 15 "Not available" 14 "Nonrecoverable fault" 2 "Direction of travel" 1 "Body of hitch" 0 "Main body of machine" ;
VAL_ 2365293566 FrontHitchYawAngleActualCtrlMode 15 "Not available" 14 "Error indication" 5 "Auto ctrl: pos. control" 4 "Auto ctrl: Bas. curvature mode" 3 "Auto ctrl: Steering wheels" 2 "Floating mode" 1 "Direct hydraulic valve control" 0 "Disabled, yaw angle is locked" ;
VAL_ 2621308670 VSpeedIncAggressivenessReq_VS 65535 "NotAvailable" 65279 "Error" 64510 "SetToMaximumAggressiveness" 64511 "SetAsPerTIMServerSettings" 64509 "SetToMinimumAggressiveness" 0 "ContinueLastAppliedAggressiveness" ;
VAL_ 2621308670 VSpeedDecAggressivenessReq_VS 65535 "NotAvailable" 65279 "Error" 64510 "SetToMaximumAggressiveness" 64511 "SetAsPerTIMServerSettings" 64509 "SetToMinimumAggressiveness" 0 "ContinueLastAppliedAggressiveness" ;
VAL_ 2621308670 RSpeedIncAggressivenessReq_RPTO 65535 "NotAvailable" 65279 "Error" 64510 "SetToMaximumAggressiveness" 64511 "SetAsPerTIMServerSettings" 64509 "SetToMinimumAggressiveness" 0 "ContinueLastAppliedAggressiveness" ;
VAL_ 2621308670 RSpeedIncAggressivenessReq_FPTO 65535 "NotAvailable" 65279 "Error" 64510 "SetToMaximumAggressiveness" 64511 "SetAsPerTIMServerSettings" 64509 "SetToMinimumAggressiveness" 0 "ContinueLastAppliedAggressiveness" ;
VAL_ 2621308670 RSpeedDecAggressivenessReq_RPTO 65535 "NotAvailable" 65279 "Error" 64510 "SetToMaximumAggressiveness" 64511 "SetAsPerTIMServerSettings" 64509 "SetToMinimumAggressiveness" 0 "ContinueLastAppliedAggressiveness" ;
VAL_ 2621308670 RSpeedDecAggressivenessReq_FPTO 65535 "NotAvailable" 65279 "Error" 64510 "SetToMaximumAggressiveness" 64511 "SetAsPerTIMServerSettings" 64509 "SetToMinimumAggressiveness" 0 "ContinueLastAppliedAggressiveness" ;
VAL_ 2621308670 PositionIncAggressivenessReq_RTL 65535 "NotAvailable" 65279 "Error" 64510 "SetToMaximumAggressiveness" 64511 "SetAsPerTIMServerSettings" 64509 "SetToMinimumAggressiveness" 0 "ContinueLastAppliedAggressiveness" ;
VAL_ 2621308670 PositionIncAggressivenessReq_RH 65535 "NotAvailable" 65279 "Error" 64510 "SetToMaximumAggressiveness" 64511 "SetAsPerTIMServerSettings" 64509 "SetToMinimumAggressiveness" 0 "ContinueLastAppliedAggressiveness" ;
VAL_ 2621308670 PositionIncAggressivenessReq_FTL 65535 "NotAvailable" 65279 "Error" 64510 "SetToMaximumAggressiveness" 64511 "SetAsPerTIMServerSettings" 64509 "SetToMinimumAggressiveness" 0 "ContinueLastAppliedAggressiveness" ;
VAL_ 2621308670 PositionIncAggressivenessReq_FH 65535 "NotAvailable" 65279 "Error" 64510 "SetToMaximumAggressiveness" 64511 "SetAsPerTIMServerSettings" 64509 "SetToMinimumAggressiveness" 0 "ContinueLastAppliedAggressiveness" ;
VAL_ 2621308670 PositionDecAggressivenessReq_RTL 65535 "NotAvailable" 65279 "Error" 64510 "SetToMaximumAggressiveness" 64511 "SetAsPerTIMServerSettings" 64509 "SetToMinimumAggressiveness" 0 "ContinueLastAppliedAggressiveness" ;
VAL_ 2621308670 PositionDecAggressivenessReq_RH 65535 "NotAvailable" 65279 "Error" 64510 "SetToMaximumAggressiveness" 64511 "SetAsPerTIMServerSettings" 64509 "SetToMinimumAggressiveness" 0 "ContinueLastAppliedAggressiveness" ;
VAL_ 2621308670 PositionDecAggressivenessReq_FTL 65535 "NotAvailable" 65279 "Error" 64510 "SetToMaximumAggressiveness" 64511 "SetAsPerTIMServerSettings" 64509 "SetToMinimumAggressiveness" 0 "ContinueLastAppliedAggressiveness" ;
VAL_ 2621308670 PositionDecAggressivenessReq_FH 65535 "NotAvailable" 65279 "Error" 64510 "SetToMaximumAggressiveness" 64511 "SetAsPerTIMServerSettings" 64509 "SetToMinimumAggressiveness" 0 "ContinueLastAppliedAggressiveness" ;
VAL_ 2621308670 FlowIncAggressivenessReq_AV32 65279 "Error" 64510 "SetToMaximumAggressiveness" 65535 "NotAvailable" 64511 "SetAsPerTIMServerSettings" 64509 "SetToMinimumAggressiveness" 0 "ContinueLastAppliedAggressiveness" ;
VAL_ 2621308670 FlowIncAggressivenessReq_AV31 65279 "Error" 64510 "SetToMaximumAggressiveness" 65535 "NotAvailable" 64511 "SetAsPerTIMServerSettings" 64509 "SetToMinimumAggressiveness" 0 "ContinueLastAppliedAggressiveness" ;
VAL_ 2621308670 FlowIncAggressivenessReq_AV30 65279 "Error" 64510 "SetToMaximumAggressiveness" 65535 "NotAvailable" 64511 "SetAsPerTIMServerSettings" 64509 "SetToMinimumAggressiveness" 0 "ContinueLastAppliedAggressiveness" ;
VAL_ 2621308670 FlowIncAggressivenessReq_AV29 65279 "Error" 64510 "SetToMaximumAggressiveness" 65535 "NotAvailable" 64511 "SetAsPerTIMServerSettings" 64509 "SetToMinimumAggressiveness" 0 "ContinueLastAppliedAggressiveness" ;
VAL_ 2621308670 FlowIncAggressivenessReq_AV28 65279 "Error" 64510 "SetToMaximumAggressiveness" 65535 "NotAvailable" 64511 "SetAsPerTIMServerSettings" 64509 "SetToMinimumAggressiveness" 0 "ContinueLastAppliedAggressiveness" ;
VAL_ 2621308670 FlowIncAggressivenessReq_AV27 65279 "Error" 64510 "SetToMaximumAggressiveness" 65535 "NotAvailable" 64511 "SetAsPerTIMServerSettings" 64509 "SetToMinimumAggressiveness" 0 "ContinueLastAppliedAggressiveness" ;
VAL_ 2621308670 FlowIncAggressivenessReq_AV26 65279 "Error" 64510 "SetToMaximumAggressiveness" 65535 "NotAvailable" 64511 "SetAsPerTIMServerSettings" 64509 "SetToMinimumAggressiveness" 0 "ContinueLastAppliedAggressiveness" ;
VAL_ 2621308670 FlowIncAggressivenessReq_AV25 65279 "Error" 64510 "SetToMaximumAggressiveness" 65535 "NotAvailable" 64511 "SetAsPerTIMServerSettings" 64509 "SetToMinimumAggressiveness" 0 "ContinueLastAppliedAggressiveness" ;
VAL_ 2621308670 FlowIncAggressivenessReq_AV24 65279 "Error" 64510 "SetToMaximumAggressiveness" 65535 "NotAvailable" 64511 "SetAsPerTIMServerSettings" 64509 "SetToMinimumAggressiveness" 0 "ContinueLastAppliedAggressiveness" ;
VAL_ 2621308670 FlowIncAggressivenessReq_AV23 65279 "Error" 64510 "SetToMaximumAggressiveness" 65535 "NotAvailable" 64511 "SetAsPerTIMServerSettings" 64509 "SetToMinimumAggressiveness" 0 "ContinueLastAppliedAggressiveness" ;
VAL_ 2621308670 FlowIncAggressivenessReq_AV22 65279 "Error" 64510 "SetToMaximumAggressiveness" 65535 "NotAvailable" 64511 "SetAsPerTIMServerSettings" 64509 "SetToMinimumAggressiveness" 0 "ContinueLastAppliedAggressiveness" ;
VAL_ 2621308670 FlowIncAggressivenessReq_AV21 65279 "Error" 64510 "SetToMaximumAggressiveness" 65535 "NotAvailable" 64511 "SetAsPerTIMServerSettings" 64509 "SetToMinimumAggressiveness" 0 "ContinueLastAppliedAggressiveness" ;
VAL_ 2621308670 FlowIncAggressivenessReq_AV20 65279 "Error" 64510 "SetToMaximumAggressiveness" 65535 "NotAvailable" 64511 "SetAsPerTIMServerSettings" 64509 "SetToMinimumAggressiveness" 0 "ContinueLastAppliedAggressiveness" ;
VAL_ 2621308670 FlowIncAggressivenessReq_AV19 65279 "Error" 64510 "SetToMaximumAggressiveness" 65535 "NotAvailable" 64511 "SetAsPerTIMServerSettings" 64509 "SetToMinimumAggressiveness" 0 "ContinueLastAppliedAggressiveness" ;
VAL_ 2621308670 FlowIncAggressivenessReq_AV18 65279 "Error" 64510 "SetToMaximumAggressiveness" 65535 "NotAvailable" 64511 "SetAsPerTIMServerSettings" 64509 "SetToMinimumAggressiveness" 0 "ContinueLastAppliedAggressiveness" ;
VAL_ 2621308670 FlowIncAggressivenessReq_AV17 65279 "Error" 64510 "SetToMaximumAggressiveness" 65535 "NotAvailable" 64511 "SetAsPerTIMServerSettings" 64509 "SetToMinimumAggressiveness" 0 "ContinueLastAppliedAggressiveness" ;
VAL_ 2621308670 FlowIncAggressivenessReq_AV16 65279 "Error" 64510 "SetToMaximumAggressiveness" 65535 "NotAvailable" 64511 "SetAsPerTIMServerSettings" 64509 "SetToMinimumAggressiveness" 0 "ContinueLastAppliedAggressiveness" ;
VAL_ 2621308670 FlowIncAggressivenessReq_AV15 65279 "Error" 64510 "SetToMaximumAggressiveness" 65535 "NotAvailable" 64511 "SetAsPerTIMServerSettings" 64509 "SetToMinimumAggressiveness" 0 "ContinueLastAppliedAggressiveness" ;
VAL_ 2621308670 FlowIncAggressivenessReq_AV14 65279 "Error" 64510 "SetToMaximumAggressiveness" 65535 "NotAvailable" 64511 "SetAsPerTIMServerSettings" 64509 "SetToMinimumAggressiveness" 0 "ContinueLastAppliedAggressiveness" ;
VAL_ 2621308670 FlowIncAggressivenessReq_AV13 65279 "Error" 64510 "SetToMaximumAggressiveness" 65535 "NotAvailable" 64511 "SetAsPerTIMServerSettings" 64509 "SetToMinimumAggressiveness" 0 "ContinueLastAppliedAggressiveness" ;
VAL_ 2621308670 FlowIncAggressivenessReq_AV12 65279 "Error" 64510 "SetToMaximumAggressiveness" 65535 "NotAvailable" 64511 "SetAsPerTIMServerSettings" 64509 "SetToMinimumAggressiveness" 0 "ContinueLastAppliedAggressiveness" ;
VAL_ 2621308670 FlowIncAggressivenessReq_AV11 65279 "Error" 64510 "SetToMaximumAggressiveness" 65535 "NotAvailable" 64511 "SetAsPerTIMServerSettings" 64509 "SetToMinimumAggressiveness" 0 "ContinueLastAppliedAggressiveness" ;
VAL_ 2621308670 FlowIncAggressivenessReq_AV10 65279 "Error" 64510 "SetToMaximumAggressiveness" 65535 "NotAvailable" 64511 "SetAsPerTIMServerSettings" 64509 "SetToMinimumAggressiveness" 0 "ContinueLastAppliedAggressiveness" ;
VAL_ 2621308670 FlowIncAggressivenessReq_AV09 65279 "Error" 64510 "SetToMaximumAggressiveness" 65535 "NotAvailable" 64511 "SetAsPerTIMServerSettings" 64509 "SetToMinimumAggressiveness" 0 "ContinueLastAppliedAggressiveness" ;
VAL_ 2621308670 FlowIncAggressivenessReq_AV08 65279 "Error" 64510 "SetToMaximumAggressiveness" 65535 "NotAvailable" 64511 "SetAsPerTIMServerSettings" 64509 "SetToMinimumAggressiveness" 0 "ContinueLastAppliedAggressiveness" ;
VAL_ 2621308670 FlowIncAggressivenessReq_AV07 65279 "Error" 64510 "SetToMaximumAggressiveness" 65535 "NotAvailable" 64511 "SetAsPerTIMServerSettings" 64509 "SetToMinimumAggressiveness" 0 "ContinueLastAppliedAggressiveness" ;
VAL_ 2621308670 FlowIncAggressivenessReq_AV06 65279 "Error" 64510 "SetToMaximumAggressiveness" 65535 "NotAvailable" 64511 "SetAsPerTIMServerSettings" 64509 "SetToMinimumAggressiveness" 0 "ContinueLastAppliedAggressiveness" ;
VAL_ 2621308670 FlowIncAggressivenessReq_AV05 65279 "Error" 64510 "SetToMaximumAggressiveness" 65535 "NotAvailable" 64511 "SetAsPerTIMServerSettings" 64509 "SetToMinimumAggressiveness" 0 "ContinueLastAppliedAggressiveness" ;
VAL_ 2621308670 FlowIncAggressivenessReq_AV04 65279 "Error" 64510 "SetToMaximumAggressiveness" 65535 "NotAvailable" 64511 "SetAsPerTIMServerSettings" 64509 "SetToMinimumAggressiveness" 0 "ContinueLastAppliedAggressiveness" ;
VAL_ 2621308670 FlowIncAggressivenessReq_AV03 65279 "Error" 64510 "SetToMaximumAggressiveness" 65535 "NotAvailable" 64511 "SetAsPerTIMServerSettings" 64509 "SetToMinimumAggressiveness" 0 "ContinueLastAppliedAggressiveness" ;
VAL_ 2621308670 FlowIncAggressivenessReq_AV02 65279 "Error" 64510 "SetToMaximumAggressiveness" 65535 "NotAvailable" 64511 "SetAsPerTIMServerSettings" 64509 "SetToMinimumAggressiveness" 0 "ContinueLastAppliedAggressiveness" ;
VAL_ 2621308670 FlowIncAggressivenessReq_AV01 65279 "Error" 64510 "SetToMaximumAggressiveness" 65535 "NotAvailable" 64511 "SetAsPerTIMServerSettings" 64509 "SetToMinimumAggressiveness" 0 "ContinueLastAppliedAggressiveness" ;
VAL_ 2621308670 FlowDecAggressivenessReq_AV32 65279 "Error" 64510 "SetToMaximumAggressiveness" 65535 "NotAvailable" 64511 "SetAsPerTIMServerSettings" 64509 "SetToMinimumAggressiveness" 0 "ContinueLastAppliedAggressiveness" ;
VAL_ 2621308670 FlowDecAggressivenessReq_AV31 65279 "Error" 64510 "SetToMaximumAggressiveness" 65535 "NotAvailable" 64511 "SetAsPerTIMServerSettings" 64509 "SetToMinimumAggressiveness" 0 "ContinueLastAppliedAggressiveness" ;
VAL_ 2621308670 FlowDecAggressivenessReq_AV30 65279 "Error" 64510 "SetToMaximumAggressiveness" 65535 "NotAvailable" 64511 "SetAsPerTIMServerSettings" 64509 "SetToMinimumAggressiveness" 0 "ContinueLastAppliedAggressiveness" ;
VAL_ 2621308670 FlowDecAggressivenessReq_AV29 65279 "Error" 64510 "SetToMaximumAggressiveness" 65535 "NotAvailable" 64511 "SetAsPerTIMServerSettings" 64509 "SetToMinimumAggressiveness" 0 "ContinueLastAppliedAggressiveness" ;
VAL_ 2621308670 FlowDecAggressivenessReq_AV28 65279 "Error" 64510 "SetToMaximumAggressiveness" 65535 "NotAvailable" 64511 "SetAsPerTIMServerSettings" 64509 "SetToMinimumAggressiveness" 0 "ContinueLastAppliedAggressiveness" ;
VAL_ 2621308670 FlowDecAggressivenessReq_AV27 65279 "Error" 64510 "SetToMaximumAggressiveness" 65535 "NotAvailable" 64511 "SetAsPerTIMServerSettings" 64509 "SetToMinimumAggressiveness" 0 "ContinueLastAppliedAggressiveness" ;
VAL_ 2621308670 FlowDecAggressivenessReq_AV26 65279 "Error" 64510 "SetToMaximumAggressiveness" 65535 "NotAvailable" 64511 "SetAsPerTIMServerSettings" 64509 "SetToMinimumAggressiveness" 0 "ContinueLastAppliedAggressiveness" ;
VAL_ 2621308670 FlowDecAggressivenessReq_AV25 65279 "Error" 64510 "SetToMaximumAggressiveness" 65535 "NotAvailable" 64511 "SetAsPerTIMServerSettings" 64509 "SetToMinimumAggressiveness" 0 "ContinueLastAppliedAggressiveness" ;
VAL_ 2621308670 FlowDecAggressivenessReq_AV24 65279 "Error" 64510 "SetToMaximumAggressiveness" 65535 "NotAvailable" 64511 "SetAsPerTIMServerSettings" 64509 "SetToMinimumAggressiveness" 0 "ContinueLastAppliedAggressiveness" ;
VAL_ 2621308670 FlowDecAggressivenessReq_AV23 65279 "Error" 64510 "SetToMaximumAggressiveness" 65535 "NotAvailable" 64511 "SetAsPerTIMServerSettings" 64509 "SetToMinimumAggressiveness" 0 "ContinueLastAppliedAggressiveness" ;
VAL_ 2621308670 FlowDecAggressivenessReq_AV22 65279 "Error" 64510 "SetToMaximumAggressiveness" 65535 "NotAvailable" 64511 "SetAsPerTIMServerSettings" 64509 "SetToMinimumAggressiveness" 0 "ContinueLastAppliedAggressiveness" ;
VAL_ 2621308670 FlowDecAggressivenessReq_AV21 65279 "Error" 64510 "SetToMaximumAggressiveness" 65535 "NotAvailable" 64511 "SetAsPerTIMServerSettings" 64509 "SetToMinimumAggressiveness" 0 "ContinueLastAppliedAggressiveness" ;
VAL_ 2621308670 FlowDecAggressivenessReq_AV20 65279 "Error" 64510 "SetToMaximumAggressiveness" 65535 "NotAvailable" 64511 "SetAsPerTIMServerSettings" 64509 "SetToMinimumAggressiveness" 0 "ContinueLastAppliedAggressiveness" ;
VAL_ 2621308670 FlowDecAggressivenessReq_AV19 65279 "Error" 64510 "SetToMaximumAggressiveness" 65535 "NotAvailable" 64511 "SetAsPerTIMServerSettings" 64509 "SetToMinimumAggressiveness" 0 "ContinueLastAppliedAggressiveness" ;
VAL_ 2621308670 FlowDecAggressivenessReq_AV18 65279 "Error" 64510 "SetToMaximumAggressiveness" 65535 "NotAvailable" 64511 "SetAsPerTIMServerSettings" 64509 "SetToMinimumAggressiveness" 0 "ContinueLastAppliedAggressiveness" ;
VAL_ 2621308670 FlowDecAggressivenessReq_AV17 65279 "Error" 64510 "SetToMaximumAggressiveness" 65535 "NotAvailable" 64511 "SetAsPerTIMServerSettings" 64509 "SetToMinimumAggressiveness" 0 "ContinueLastAppliedAggressiveness" ;
VAL_ 2621308670 FlowDecAggressivenessReq_AV16 65279 "Error" 64510 "SetToMaximumAggressiveness" 65535 "NotAvailable" 64511 "SetAsPerTIMServerSettings" 64509 "SetToMinimumAggressiveness" 0 "ContinueLastAppliedAggressiveness" ;
VAL_ 2621308670 FlowDecAggressivenessReq_AV15 65279 "Error" 64510 "SetToMaximumAggressiveness" 65535 "NotAvailable" 64511 "SetAsPerTIMServerSettings" 64509 "SetToMinimumAggressiveness" 0 "ContinueLastAppliedAggressiveness" ;
VAL_ 2621308670 FlowDecAggressivenessReq_AV14 65279 "Error" 64510 "SetToMaximumAggressiveness" 65535 "NotAvailable" 64511 "SetAsPerTIMServerSettings" 64509 "SetToMinimumAggressiveness" 0 "ContinueLastAppliedAggressiveness" ;
VAL_ 2621308670 FlowDecAggressivenessReq_AV13 65279 "Error" 64510 "SetToMaximumAggressiveness" 65535 "NotAvailable" 64511 "SetAsPerTIMServerSettings" 64509 "SetToMinimumAggressiveness" 0 "ContinueLastAppliedAggressiveness" ;
VAL_ 2621308670 FlowDecAggressivenessReq_AV12 65279 "Error" 64510 "SetToMaximumAggressiveness" 65535 "NotAvailable" 64511 "SetAsPerTIMServerSettings" 64509 "SetToMinimumAggressiveness" 0 "ContinueLastAppliedAggressiveness" ;
VAL_ 2621308670 FlowDecAggressivenessReq_AV11 65279 "Error" 64510 "SetToMaximumAggressiveness" 65535 "NotAvailable" 64511 "SetAsPerTIMServerSettings" 64509 "SetToMinimumAggressiveness" 0 "ContinueLastAppliedAggressiveness" ;
VAL_ 2621308670 FlowDecAggressivenessReq_AV10 65279 "Error" 64510 "SetToMaximumAggressiveness" 65535 "NotAvailable" 64511 "SetAsPerTIMServerSettings" 64509 "SetToMinimumAggressiveness" 0 "ContinueLastAppliedAggressiveness" ;
VAL_ 2621308670 FlowDecAggressivenessReq_AV09 65279 "Error" 64510 "SetToMaximumAggressiveness" 65535 "NotAvailable" 64511 "SetAsPerTIMServerSettings" 64509 "SetToMinimumAggressiveness" 0 "ContinueLastAppliedAggressiveness" ;
VAL_ 2621308670 FlowDecAggressivenessReq_AV08 65279 "Error" 64510 "SetToMaximumAggressiveness" 65535 "NotAvailable" 64511 "SetAsPerTIMServerSettings" 64509 "SetToMinimumAggressiveness" 0 "ContinueLastAppliedAggressiveness" ;
VAL_ 2621308670 FlowDecAggressivenessReq_AV07 65279 "Error" 64510 "SetToMaximumAggressiveness" 65535 "NotAvailable" 64511 "SetAsPerTIMServerSettings" 64509 "SetToMinimumAggressiveness" 0 "ContinueLastAppliedAggressiveness" ;
VAL_ 2621308670 FlowDecAggressivenessReq_AV06 65279 "Error" 64510 "SetToMaximumAggressiveness" 65535 "NotAvailable" 64511 "SetAsPerTIMServerSettings" 64509 "SetToMinimumAggressiveness" 0 "ContinueLastAppliedAggressiveness" ;
VAL_ 2621308670 FlowDecAggressivenessReq_AV05 65279 "Error" 64510 "SetToMaximumAggressiveness" 65535 "NotAvailable" 64511 "SetAsPerTIMServerSettings" 64509 "SetToMinimumAggressiveness" 0 "ContinueLastAppliedAggressiveness" ;
VAL_ 2621308670 FlowDecAggressivenessReq_AV04 65279 "Error" 64510 "SetToMaximumAggressiveness" 65535 "NotAvailable" 64511 "SetAsPerTIMServerSettings" 64509 "SetToMinimumAggressiveness" 0 "ContinueLastAppliedAggressiveness" ;
VAL_ 2621308670 FlowDecAggressivenessReq_AV03 65279 "Error" 64510 "SetToMaximumAggressiveness" 65535 "NotAvailable" 64511 "SetAsPerTIMServerSettings" 64509 "SetToMinimumAggressiveness" 0 "ContinueLastAppliedAggressiveness" ;
VAL_ 2621308670 FlowDecAggressivenessReq_AV02 65279 "Error" 64510 "SetToMaximumAggressiveness" 65535 "NotAvailable" 64511 "SetAsPerTIMServerSettings" 64509 "SetToMinimumAggressiveness" 0 "ContinueLastAppliedAggressiveness" ;
VAL_ 2621308670 FlowDecAggressivenessReq_AV01 65279 "Error" 64510 "SetToMaximumAggressiveness" 65535 "NotAvailable" 64511 "SetAsPerTIMServerSettings" 64509 "SetToMinimumAggressiveness" 0 "ContinueLastAppliedAggressiveness" ;
VAL_ 2621308670 CurvatureAggressivenessReq_EG 65535 "NotAvailable" 65279 "Error" 64510 "SetToMaximumAggressiveness" 0 "ContinueLastAppliedAggressiveness" 64511 "SetAsPerTIMSserverSettings" 64509 "SetToMinimumAggressiveness" ;
VAL_ 2621308670 SecurityByte_VS 17 "LinearMotion_Request" 0 "Parametrization_Request" ;
VAL_ 2621308670 SecurityByte_RTL 17 "PercentagePosition_Request" 0 "Parametrization_Request" ;
VAL_ 2621308670 SecurityByte_RPTO 17 "RotationalSpeed_Request" ;
VAL_ 2621308670 SecurityByte_RH 17 "PercentagePosition_Request" ;
VAL_ 2621308670 SecurityByte_FTL 17 "PercentagePosition_Request" 0 "Parametrization_Request" ;
VAL_ 2621308670 SecurityByte_FPTO 17 "RotationalSpeed_Request" ;
VAL_ 2621308670 SecurityByte_FH 17 "PercentagePosition_Request" ;
VAL_ 2621308670 SecurityByte_EG 17 "Curvature_Request" ;
VAL_ 2621308670 SecurityByte_AV32 17 "PercentageFlow_Request" ;
VAL_ 2621308670 SecurityByte_AV31 17 "PercentageFlow_Request" ;
VAL_ 2621308670 SecurityByte_AV30 17 "PercentageFlow_Request" ;
VAL_ 2621308670 SecurityByte_AV29 17 "PercentageFlow_Request" ;
VAL_ 2621308670 SecurityByte_AV28 17 "PercentageFlow_Request" ;
VAL_ 2621308670 SecurityByte_AV27 17 "PercentageFlow_Request" ;
VAL_ 2621308670 SecurityByte_AV26 17 "PercentageFlow_Request" ;
VAL_ 2621308670 SecurityByte_AV25 17 "PercentageFlow_Request" ;
VAL_ 2621308670 SecurityByte_AV24 17 "PercentageFlow_Request" ;
VAL_ 2621308670 SecurityByte_AV23 17 "PercentageFlow_Request" ;
VAL_ 2621308670 SecurityByte_AV22 17 "PercentageFlow_Request" ;
VAL_ 2621308670 SecurityByte_AV21 17 "PercentageFlow_Request" ;
VAL_ 2621308670 SecurityByte_AV20 17 "PercentageFlow_Request" ;
VAL_ 2621308670 SecurityByte_AV19 17 "PercentageFlow_Request" ;
VAL_ 2621308670 SecurityByte_AV18 17 "PercentageFlow_Request" ;
VAL_ 2621308670 SecurityByte_AV17 17 "PercentageFlow_Request" ;
VAL_ 2621308670 SecurityByte_AV16 17 "PercentageFlow_Request" ;
VAL_ 2621308670 SecurityByte_AV15 17 "PercentageFlow_Request" ;
VAL_ 2621308670 SecurityByte_AV14 17 "PercentageFlow_Request" ;
VAL_ 2621308670 SecurityByte_AV13 17 "PercentageFlow_Request" ;
VAL_ 2621308670 SecurityByte_AV12 17 "PercentageFlow_Request" ;
VAL_ 2621308670 SecurityByte_AV11 17 "PercentageFlow_Request" ;
VAL_ 2621308670 SecurityByte_AV10 17 "PercentageFlow_Request" ;
VAL_ 2621308670 SecurityByte_AV09 17 "PercentageFlow_Request" ;
VAL_ 2621308670 SecurityByte_AV08 17 "PercentageFlow_Request" ;
VAL_ 2621308670 SecurityByte_AV07 17 "PercentageFlow_Request" ;
VAL_ 2621308670 SecurityByte_AV06 17 "PercentageFlow_Request" ;
VAL_ 2621308670 SecurityByte_AV05 17 "PercentageFlow_Request" ;
VAL_ 2621308670 SecurityByte_AV04 17 "PercentageFlow_Request" ;
VAL_ 2621308670 SecurityByte_AV03 17 "PercentageFlow_Request" ;
VAL_ 2621308670 SecurityByte_AV02 17 "PercentageFlow_Request" ;
VAL_ 2621308670 SecurityByte_AV01 17 "PercentageFlow_Request" ;
VAL_ 2621308670 PositionRequest_RTL 64511 "ReadyToControl" 64509 "ReleaseControlReqOperatorAction" 64259 "ExtendUntilStopRequest" 64258 "RetractUntilStopRequest" 64257 "Stop" 64256 "Float" ;
VAL_ 2621308670 PositionRequest_FTL 64511 "ReadyToControl" 64509 "ReleaseControlReqOperatorAction" 64259 "ExtendUntilStopRequest" 64258 "RetractUntilStopRequest" 64257 "Stop" 64256 "Float" ;
VAL_ 2621308670 ControlMode1_VS 0 "GeneralParametrizationRequest" ;
VAL_ 2621308670 ControlMode1_RTL 0 "GeneralParametrizationRequest" ;
VAL_ 2621308670 ControlMode1_FTL 0 "GeneralParametrizationRequest" ;
VAL_ 2621308670 MsgType_RTL 65 "PercentagePosition_AggressivenessRequest" 17 "PercentagePosition_Request" 0 "Parametrization_Request" ;
VAL_ 2621308670 MsgType_FTL 65 "PercentagePosition_AggressivenessRequest" 17 "PercentagePosition_Request" 0 "Parametrization_Request" ;
VAL_ 2621308670 MsgType_EG 65 "Curvature_AggressivenessRequest" 17 "Curvature_Request" ;
VAL_ 2621308670 MsgType_VS 65 "LinearMotion_AggressivenessRequest" 17 "LinearMotion_Request" 0 "Parametrization_Request" ;
VAL_ 2621308670 MsgType_RH 65 "PercentagePosition_AggressivenessRequest" 17 "PercentagePosition_Request" ;
VAL_ 2621308670 MsgType_FH 65 "PercentagePosition_AggressivenessRequest" 17 "PercentagePosition_Request" ;
VAL_ 2621308670 MsgType_RPTO 65 "RotationalSpeed_AggressivenessRequest" 17 "RotationalSpeed_Request" ;
VAL_ 2621308670 MsgType_FPTO 65 "RotationalSpeed_AggressivenessRequest" 17 "RotationalSpeed_Request" ;
VAL_ 2621308670 MsgType_AV32 65 "PercentageFlow_AggressivenessRequest" 17 "PercentageFlow_Request" ;
VAL_ 2621308670 MsgType_AV31 65 "PercentageFlow_AggressivenessRequest" 17 "PercentageFlow_Request" ;
VAL_ 2621308670 MsgType_AV30 65 "PercentageFlow_AggressivenessRequest" 17 "PercentageFlow_Request" ;
VAL_ 2621308670 MsgType_AV29 65 "PercentageFlow_AggressivenessRequest" 17 "PercentageFlow_Request" ;
VAL_ 2621308670 MsgType_AV28 65 "PercentageFlow_AggressivenessRequest" 17 "PercentageFlow_Request" ;
VAL_ 2621308670 MsgType_AV27 65 "PercentageFlow_AggressivenessRequest" 17 "PercentageFlow_Request" ;
VAL_ 2621308670 MsgType_AV26 65 "PercentageFlow_AggressivenessRequest" 17 "PercentageFlow_Request" ;
VAL_ 2621308670 MsgType_AV25 65 "PercentageFlow_AggressivenessRequest" 17 "PercentageFlow_Request" ;
VAL_ 2621308670 MsgType_AV24 65 "PercentageFlow_AggressivenessRequest" 17 "PercentageFlow_Request" ;
VAL_ 2621308670 MsgType_AV23 65 "PercentageFlow_AggressivenessRequest" 17 "PercentageFlow_Request" ;
VAL_ 2621308670 MsgType_AV22 65 "PercentageFlow_AggressivenessRequest" 17 "PercentageFlow_Request" ;
VAL_ 2621308670 MsgType_AV21 65 "PercentageFlow_AggressivenessRequest" 17 "PercentageFlow_Request" ;
VAL_ 2621308670 MsgType_AV20 65 "PercentageFlow_AggressivenessRequest" 17 "PercentageFlow_Request" ;
VAL_ 2621308670 MsgType_AV19 65 "PercentageFlow_AggressivenessRequest" 17 "PercentageFlow_Request" ;
VAL_ 2621308670 MsgType_AV18 65 "PercentageFlow_AggressivenessRequest" 17 "PercentageFlow_Request" ;
VAL_ 2621308670 MsgType_AV17 65 "PercentageFlow_AggressivenessRequest" 17 "PercentageFlow_Request" ;
VAL_ 2621308670 MsgType_AV16 65 "PercentageFlow_AggressivenessRequest" 17 "PercentageFlow_Request" ;
VAL_ 2621308670 MsgType_AV15 65 "PercentageFlow_AggressivenessRequest" 17 "PercentageFlow_Request" ;
VAL_ 2621308670 MsgType_AV14 65 "PercentageFlow_AggressivenessRequest" 17 "PercentageFlow_Request" ;
VAL_ 2621308670 MsgType_AV13 65 "PercentageFlow_AggressivenessRequest" 17 "PercentageFlow_Request" ;
VAL_ 2621308670 MsgType_AV12 65 "PercentageFlow_AggressivenessRequest" 17 "PercentageFlow_Request" ;
VAL_ 2621308670 MsgType_AV11 65 "PercentageFlow_AggressivenessRequest" 17 "PercentageFlow_Request" ;
VAL_ 2621308670 MsgType_AV10 65 "PercentageFlow_AggressivenessRequest" 17 "PercentageFlow_Request" ;
VAL_ 2621308670 MsgType_AV09 65 "PercentageFlow_AggressivenessRequest" 17 "PercentageFlow_Request" ;
VAL_ 2621308670 MsgType_AV08 65 "PercentageFlow_AggressivenessRequest" 17 "PercentageFlow_Request" ;
VAL_ 2621308670 MsgType_AV07 65 "PercentageFlow_AggressivenessRequest" 17 "PercentageFlow_Request" ;
VAL_ 2621308670 MsgType_AV06 65 "PercentageFlow_AggressivenessRequest" 17 "PercentageFlow_Request" ;
VAL_ 2621308670 MsgType_AV05 65 "PercentageFlow_AggressivenessRequest" 17 "PercentageFlow_Request" ;
VAL_ 2621308670 MsgType_AV04 65 "PercentageFlow_AggressivenessRequest" 17 "PercentageFlow_Request" ;
VAL_ 2621308670 MsgType_AV03 65 "PercentageFlow_AggressivenessRequest" 17 "PercentageFlow_Request" ;
VAL_ 2621308670 MsgType_AV02 65 "PercentageFlow_AggressivenessRequest" 17 "PercentageFlow_Request" ;
VAL_ 2621308670 MsgType_AV01 65 "PercentageFlow_AggressivenessRequest" 17 "PercentageFlow_Request" ;
VAL_ 2621308670 TIMFunctionID 72 "RearTopLinkage" 71 "FrontTopLinkage" 32 "TIM_AuxValve32" 70 "ExternalGuidance" 68 "VehicleSpeed" 67 "RearHitch" 66 "FrontHitch" 65 "RearPTO" 64 "FrontPTO" 31 "TIM_AuxValve31" 30 "TIM_AuxValve30" 29 "TIM_AuxValve29" 28 "TIM_AuxValve28" 27 "TIM_AuxValve27" 26 "TIM_AuxValve26" 25 "TIM_AuxValve25" 24 "TIM_AuxValve24" 23 "TIM_AuxValve23" 22 "TIM_AuxValve22" 21 "TIM_AuxValve21" 20 "TIM_AuxValve20" 19 "TIM_AuxValve19" 18 "TIM_AuxValve18" 17 "TIM_AuxValve17" 16 "TIM_AuxValve16" 15 "TIM_AuxValve15" 14 "TIM_AuxValve14" 13 "TIM_AuxValve13" 12 "TIM_AuxValve12" 11 "TIM_AuxValve11" 10 "TIM_AuxValve10" 9 "TIM_AuxValve9" 8 "TIM_AuxValve8" 7 "TIM_AuxValve7" 6 "TIM_AuxValve6" 5 "TIM_AuxValve5" 4 "TIM_AuxValve4" 3 "TIM_AuxValve3" 2 "TIM_AuxValve2" 1 "TIM_AuxValve1" ;
VAL_ 2621308670 FlowRequest_AV32 64511 "ReadyToControl" 64509 "ReleasedControlRequestingOperatorActionBeforeFunctionValueIncreases" 64257 "Float" 64256 "ValveFullyOpened_Retract" 32128 "Block" 0 "ValveFullyOpened_Extend" ;
VAL_ 2621308670 FlowRequest_AV31 64511 "ReadyToControl" 64509 "ReleasedControlRequestingOperatorActionBeforeFunctionValueIncreases" 64257 "Float" 64256 "ValveFullyOpened_Retract" 32128 "Block" 0 "ValveFullyOpened_Extend" ;
VAL_ 2621308670 FlowRequest_AV30 64511 "ReadyToControl" 64509 "ReleasedControlRequestingOperatorActionBeforeFunctionValueIncreases" 64257 "Float" 64256 "ValveFullyOpened_Retract" 32128 "Block" 0 "ValveFullyOpened_Extend" ;
VAL_ 2621308670 FlowRequest_AV29 64511 "ReadyToControl" 64509 "ReleasedControlRequestingOperatorActionBeforeFunctionValueIncreases" 64257 "Float" 64256 "ValveFullyOpened_Retract" 32128 "Block" 0 "ValveFullyOpened_Extend" ;
VAL_ 2621308670 FlowRequest_AV28 64511 "ReadyToControl" 64509 "ReleasedControlRequestingOperatorActionBeforeFunctionValueIncreases" 64257 "Float" 64256 "ValveFullyOpened_Retract" 32128 "Block" 0 "ValveFullyOpened_Extend" ;
VAL_ 2621308670 FlowRequest_AV27 64511 "ReadyToControl" 64509 "ReleasedControlRequestingOperatorActionBeforeFunctionValueIncreases" 64257 "Float" 64256 "ValveFullyOpened_Retract" 32128 "Block" 0 "ValveFullyOpened_Extend" ;
VAL_ 2621308670 FlowRequest_AV26 64511 "ReadyToControl" 64509 "ReleasedControlRequestingOperatorActionBeforeFunctionValueIncreases" 64257 "Float" 64256 "ValveFullyOpened_Retract" 32128 "Block" 0 "ValveFullyOpened_Extend" ;
VAL_ 2621308670 FlowRequest_AV25 64511 "ReadyToControl" 64509 "ReleasedControlRequestingOperatorActionBeforeFunctionValueIncreases" 64257 "Float" 64256 "ValveFullyOpened_Retract" 32128 "Block" 0 "ValveFullyOpened_Extend" ;
VAL_ 2621308670 FlowRequest_AV24 64511 "ReadyToControl" 64509 "ReleasedControlRequestingOperatorActionBeforeFunctionValueIncreases" 64257 "Float" 64256 "ValveFullyOpened_Retract" 32128 "Block" 0 "ValveFullyOpened_Extend" ;
VAL_ 2621308670 FlowRequest_AV23 64511 "ReadyToControl" 64509 "ReleasedControlRequestingOperatorActionBeforeFunctionValueIncreases" 64257 "Float" 64256 "ValveFullyOpened_Retract" 32128 "Block" 0 "ValveFullyOpened_Extend" ;
VAL_ 2621308670 FlowRequest_AV22 64511 "ReadyToControl" 64509 "ReleasedControlRequestingOperatorActionBeforeFunctionValueIncreases" 64257 "Float" 64256 "ValveFullyOpened_Retract" 32128 "Block" 0 "ValveFullyOpened_Extend" ;
VAL_ 2621308670 FlowRequest_AV21 64511 "ReadyToControl" 64509 "ReleasedControlRequestingOperatorActionBeforeFunctionValueIncreases" 64257 "Float" 64256 "ValveFullyOpened_Retract" 32128 "Block" 0 "ValveFullyOpened_Extend" ;
VAL_ 2621308670 FlowRequest_AV20 64511 "ReadyToControl" 64509 "ReleasedControlRequestingOperatorActionBeforeFunctionValueIncreases" 64257 "Float" 64256 "ValveFullyOpened_Retract" 32128 "Block" 0 "ValveFullyOpened_Extend" ;
VAL_ 2621308670 FlowRequest_AV19 64511 "ReadyToControl" 64509 "ReleasedControlRequestingOperatorActionBeforeFunctionValueIncreases" 64257 "Float" 64256 "ValveFullyOpened_Retract" 32128 "Block" 0 "ValveFullyOpened_Extend" ;
VAL_ 2621308670 FlowRequest_AV18 64511 "ReadyToControl" 64509 "ReleasedControlRequestingOperatorActionBeforeFunctionValueIncreases" 64257 "Float" 64256 "ValveFullyOpened_Retract" 32128 "Block" 0 "ValveFullyOpened_Extend" ;
VAL_ 2621308670 FlowRequest_AV17 64511 "ReadyToControl" 64509 "ReleasedControlRequestingOperatorActionBeforeFunctionValueIncreases" 64257 "Float" 64256 "ValveFullyOpened_Retract" 32128 "Block" 0 "ValveFullyOpened_Extend" ;
VAL_ 2621308670 FlowRequest_AV16 64511 "ReadyToControl" 64509 "ReleasedControlRequestingOperatorActionBeforeFunctionValueIncreases" 64257 "Float" 64256 "ValveFullyOpened_Retract" 32128 "Block" 0 "ValveFullyOpened_Extend" ;
VAL_ 2621308670 FlowRequest_AV15 64511 "ReadyToControl" 64509 "ReleasedControlRequestingOperatorActionBeforeFunctionValueIncreases" 64257 "Float" 64256 "ValveFullyOpened_Retract" 32128 "Block" 0 "ValveFullyOpened_Extend" ;
VAL_ 2621308670 FlowRequest_AV14 64511 "ReadyToControl" 64509 "ReleasedControlRequestingOperatorActionBeforeFunctionValueIncreases" 64257 "Float" 64256 "ValveFullyOpened_Retract" 32128 "Block" 0 "ValveFullyOpened_Extend" ;
VAL_ 2621308670 FlowRequest_AV13 64511 "ReadyToControl" 64509 "ReleasedControlRequestingOperatorActionBeforeFunctionValueIncreases" 64257 "Float" 64256 "ValveFullyOpened_Retract" 32128 "Block" 0 "ValveFullyOpened_Extend" ;
VAL_ 2621308670 FlowRequest_AV12 64511 "ReadyToControl" 64509 "ReleasedControlRequestingOperatorActionBeforeFunctionValueIncreases" 64257 "Float" 64256 "ValveFullyOpened_Retract" 32128 "Block" 0 "ValveFullyOpened_Extend" ;
VAL_ 2621308670 FlowRequest_AV11 64511 "ReadyToControl" 64509 "ReleasedControlRequestingOperatorActionBeforeFunctionValueIncreases" 64257 "Float" 64256 "ValveFullyOpened_Retract" 32128 "Block" 0 "ValveFullyOpened_Extend" ;
VAL_ 2621308670 FlowRequest_AV10 64511 "ReadyToControl" 64509 "ReleasedControlRequestingOperatorActionBeforeFunctionValueIncreases" 64257 "Float" 64256 "ValveFullyOpened_Retract" 32128 "Block" 0 "ValveFullyOpened_Extend" ;
VAL_ 2621308670 FlowRequest_AV09 64511 "ReadyToControl" 64509 "ReleasedControlRequestingOperatorActionBeforeFunctionValueIncreases" 64257 "Float" 64256 "ValveFullyOpened_Retract" 32128 "Block" 0 "ValveFullyOpened_Extend" ;
VAL_ 2621308670 FlowRequest_AV08 64511 "ReadyToControl" 64509 "ReleasedControlRequestingOperatorActionBeforeFunctionValueIncreases" 64257 "Float" 64256 "ValveFullyOpened_Retract" 32128 "Block" 0 "ValveFullyOpened_Extend" ;
VAL_ 2621308670 FlowRequest_AV07 64511 "ReadyToControl" 64509 "ReleasedControlRequestingOperatorActionBeforeFunctionValueIncreases" 64257 "Float" 64256 "ValveFullyOpened_Retract" 32128 "Block" 0 "ValveFullyOpened_Extend" ;
VAL_ 2621308670 FlowRequest_AV06 64511 "ReadyToControl" 64509 "ReleasedControlRequestingOperatorActionBeforeFunctionValueIncreases" 64257 "Float" 64256 "ValveFullyOpened_Retract" 32128 "Block" 0 "ValveFullyOpened_Extend" ;
VAL_ 2621308670 FlowRequest_AV05 64511 "ReadyToControl" 64509 "ReleasedControlRequestingOperatorActionBeforeFunctionValueIncreases" 64257 "Float" 64256 "ValveFullyOpened_Retract" 32128 "Block" 0 "ValveFullyOpened_Extend" ;
VAL_ 2621308670 FlowRequest_AV04 64511 "ReadyToControl" 64509 "ReleasedControlRequestingOperatorActionBeforeFunctionValueIncreases" 64257 "Float" 64256 "ValveFullyOpened_Retract" 32128 "Block" 0 "ValveFullyOpened_Extend" ;
VAL_ 2621308670 FlowRequest_AV03 64511 "ReadyToControl" 64509 "ReleasedControlRequestingOperatorActionBeforeFunctionValueIncreases" 64257 "Float" 64256 "ValveFullyOpened_Retract" 32128 "Block" 0 "ValveFullyOpened_Extend" ;
VAL_ 2621308670 FlowRequest_AV02 64511 "ReadyToControl" 64509 "ReleasedControlRequestingOperatorActionBeforeFunctionValueIncreases" 64257 "Float" 64256 "ValveFullyOpened_Retract" 32128 "Block" 0 "ValveFullyOpened_Extend" ;
VAL_ 2621308670 PositionRequest_RH 10000 "FullRaise" 64259 "RaiseUntilStopRequest" 64258 "LowerUntilStopRequest" 0 "FullLower" 64511 "ReadyToControl" 64509 "ReleaseControlRequestingOperatorAction" 64257 "Stop" 64256 "Float" ;
VAL_ 2621308670 OutputShaftSpeedRequest_RPTO 64511 "ReadyToControl" 64509 "RequestingOperatorAction" 64256 "On_SpeedClockwiseSetByTimServer" 32128 "Off" 0 "On_SpeedCounterClockwiseSetByTimServer" ;
VAL_ 2621308670 CurvatureRequest_EG 64511 "ReadyToControl" 64509 "RequestingOperatorAwareness" 32128 "Straight" ;
VAL_ 2621308670 VehicleSpeedRequest_VS 64511 "ReadyToControl" 64510 "AcceptFunctionWithoutOperatorAwareness" 64509 "RequestingOperatorAwareness" 64256 "ForwardSpeedSetByTimServer" 32128 "Stop" 0 "ReverseSpeedSetByTimServer" ;
VAL_ 2621308670 PositionRequest_FH 10000 "FullRaise" 64259 "RaiseUntilStopRequest" 64258 "LowerUntilStopRequest" 0 "FullLower" 64511 "ReadyToControl" 64509 "ReleaseControlRequestingOperatorAction" 64257 "Stop" 64256 "Float" ;
VAL_ 2621308670 OutputShaftSpeedRequest_FPTO 64511 "ReadyToControl" 64509 "RequestingOperatorAction" 64256 "On_SpeedClockwiseSetByTimServer" 32128 "Off" 0 "On_SpeedCounterClockwiseSetByTimServer" ;
VAL_ 2621308670 FlowRequest_AV01 64511 "ReadyToControl" 64509 "ReleasedControlRequestingOperatorActionBeforeFunctionValueIncreases" 64257 "Float" 64256 "ValveFullyOpened_Retract" 32128 "Block" 0 "ValveFullyOpened_Extend" ;

SG_MUL_VAL_ 2621308670 VSpeedIncAggressivenessReq_VS MsgType_VS 65-65;
SG_MUL_VAL_ 2621308670 VSpeedDecAggressivenessReq_VS MsgType_VS 65-65;
SG_MUL_VAL_ 2621308670 RSpeedIncAggressivenessReq_RPTO MsgType_RPTO 65-65;
SG_MUL_VAL_ 2621308670 RSpeedIncAggressivenessReq_FPTO MsgType_FPTO 65-65;
SG_MUL_VAL_ 2621308670 RSpeedDecAggressivenessReq_RPTO MsgType_RPTO 65-65;
SG_MUL_VAL_ 2621308670 RSpeedDecAggressivenessReq_FPTO MsgType_FPTO 65-65;
SG_MUL_VAL_ 2621308670 PositionIncAggressivenessReq_RTL MsgType_RTL 65-65;
SG_MUL_VAL_ 2621308670 PositionIncAggressivenessReq_RH MsgType_RH 65-65;
SG_MUL_VAL_ 2621308670 PositionIncAggressivenessReq_FTL MsgType_FTL 65-65;
SG_MUL_VAL_ 2621308670 PositionIncAggressivenessReq_FH MsgType_FH 65-65;
SG_MUL_VAL_ 2621308670 PositionDecAggressivenessReq_RTL MsgType_RTL 65-65;
SG_MUL_VAL_ 2621308670 PositionDecAggressivenessReq_RH MsgType_RH 65-65;
SG_MUL_VAL_ 2621308670 PositionDecAggressivenessReq_FTL MsgType_FTL 65-65;
SG_MUL_VAL_ 2621308670 PositionDecAggressivenessReq_FH MsgType_FH 65-65;
SG_MUL_VAL_ 2621308670 FlowIncAggressivenessReq_AV32 MsgType_AV32 65-65;
SG_MUL_VAL_ 2621308670 FlowIncAggressivenessReq_AV31 MsgType_AV31 65-65;
SG_MUL_VAL_ 2621308670 FlowIncAggressivenessReq_AV30 MsgType_AV30 65-65;
SG_MUL_VAL_ 2621308670 FlowIncAggressivenessReq_AV29 MsgType_AV29 65-65;
SG_MUL_VAL_ 2621308670 FlowIncAggressivenessReq_AV28 MsgType_AV28 65-65;
SG_MUL_VAL_ 2621308670 FlowIncAggressivenessReq_AV27 MsgType_AV27 65-65;
SG_MUL_VAL_ 2621308670 FlowIncAggressivenessReq_AV26 MsgType_AV26 65-65;
SG_MUL_VAL_ 2621308670 FlowIncAggressivenessReq_AV25 MsgType_AV25 65-65;
SG_MUL_VAL_ 2621308670 FlowIncAggressivenessReq_AV24 MsgType_AV24 65-65;
SG_MUL_VAL_ 2621308670 FlowIncAggressivenessReq_AV23 MsgType_AV23 65-65;
SG_MUL_VAL_ 2621308670 FlowIncAggressivenessReq_AV22 MsgType_AV22 65-65;
SG_MUL_VAL_ 2621308670 FlowIncAggressivenessReq_AV21 MsgType_AV21 65-65;
SG_MUL_VAL_ 2621308670 FlowIncAggressivenessReq_AV20 MsgType_AV20 65-65;
SG_MUL_VAL_ 2621308670 FlowIncAggressivenessReq_AV19 MsgType_AV19 65-65;
SG_MUL_VAL_ 2621308670 FlowIncAggressivenessReq_AV18 MsgType_AV18 65-65;
SG_MUL_VAL_ 2621308670 FlowIncAggressivenessReq_AV17 MsgType_AV17 65-65;
SG_MUL_VAL_ 2621308670 FlowIncAggressivenessReq_AV16 MsgType_AV16 65-65;
SG_MUL_VAL_ 2621308670 FlowIncAggressivenessReq_AV15 MsgType_AV15 65-65;
SG_MUL_VAL_ 2621308670 FlowIncAggressivenessReq_AV14 MsgType_AV14 65-65;
SG_MUL_VAL_ 2621308670 FlowIncAggressivenessReq_AV13 MsgType_AV13 65-65;
SG_MUL_VAL_ 2621308670 FlowIncAggressivenessReq_AV12 MsgType_AV12 65-65;
SG_MUL_VAL_ 2621308670 FlowIncAggressivenessReq_AV11 MsgType_AV11 65-65;
SG_MUL_VAL_ 2621308670 FlowIncAggressivenessReq_AV10 MsgType_AV10 65-65;
SG_MUL_VAL_ 2621308670 FlowIncAggressivenessReq_AV09 MsgType_AV09 65-65;
SG_MUL_VAL_ 2621308670 FlowIncAggressivenessReq_AV08 MsgType_AV08 65-65;
SG_MUL_VAL_ 2621308670 FlowIncAggressivenessReq_AV07 MsgType_AV07 65-65;
SG_MUL_VAL_ 2621308670 FlowIncAggressivenessReq_AV06 MsgType_AV06 65-65;
SG_MUL_VAL_ 2621308670 FlowIncAggressivenessReq_AV05 MsgType_AV05 65-65;
SG_MUL_VAL_ 2621308670 FlowIncAggressivenessReq_AV04 MsgType_AV04 65-65;
SG_MUL_VAL_ 2621308670 FlowIncAggressivenessReq_AV03 MsgType_AV03 65-65;
SG_MUL_VAL_ 2621308670 FlowIncAggressivenessReq_AV02 MsgType_AV02 65-65;
SG_MUL_VAL_ 2621308670 FlowIncAggressivenessReq_AV01 MsgType_AV01 65-65;
SG_MUL_VAL_ 2621308670 FlowDecAggressivenessReq_AV32 MsgType_AV32 65-65;
SG_MUL_VAL_ 2621308670 FlowDecAggressivenessReq_AV31 MsgType_AV31 65-65;
SG_MUL_VAL_ 2621308670 FlowDecAggressivenessReq_AV30 MsgType_AV30 65-65;
SG_MUL_VAL_ 2621308670 FlowDecAggressivenessReq_AV29 MsgType_AV29 65-65;
SG_MUL_VAL_ 2621308670 FlowDecAggressivenessReq_AV28 MsgType_AV28 65-65;
SG_MUL_VAL_ 2621308670 FlowDecAggressivenessReq_AV27 MsgType_AV27 65-65;
SG_MUL_VAL_ 2621308670 FlowDecAggressivenessReq_AV26 MsgType_AV26 65-65;
SG_MUL_VAL_ 2621308670 FlowDecAggressivenessReq_AV25 MsgType_AV25 65-65;
SG_MUL_VAL_ 2621308670 FlowDecAggressivenessReq_AV24 MsgType_AV24 65-65;
SG_MUL_VAL_ 2621308670 FlowDecAggressivenessReq_AV23 MsgType_AV23 65-65;
SG_MUL_VAL_ 2621308670 FlowDecAggressivenessReq_AV22 MsgType_AV22 65-65;
SG_MUL_VAL_ 2621308670 FlowDecAggressivenessReq_AV21 MsgType_AV21 65-65;
SG_MUL_VAL_ 2621308670 FlowDecAggressivenessReq_AV20 MsgType_AV20 65-65;
SG_MUL_VAL_ 2621308670 FlowDecAggressivenessReq_AV19 MsgType_AV19 65-65;
SG_MUL_VAL_ 2621308670 FlowDecAggressivenessReq_AV18 MsgType_AV18 65-65;
SG_MUL_VAL_ 2621308670 FlowDecAggressivenessReq_AV17 MsgType_AV17 65-65;
SG_MUL_VAL_ 2621308670 FlowDecAggressivenessReq_AV16 MsgType_AV16 65-65;
SG_MUL_VAL_ 2621308670 FlowDecAggressivenessReq_AV15 MsgType_AV15 65-65;
SG_MUL_VAL_ 2621308670 FlowDecAggressivenessReq_AV14 MsgType_AV14 65-65;
SG_MUL_VAL_ 2621308670 FlowDecAggressivenessReq_AV13 MsgType_AV13 65-65;
SG_MUL_VAL_ 2621308670 FlowDecAggressivenessReq_AV12 MsgType_AV12 65-65;
SG_MUL_VAL_ 2621308670 FlowDecAggressivenessReq_AV11 MsgType_AV11 65-65;
SG_MUL_VAL_ 2621308670 FlowDecAggressivenessReq_AV10 MsgType_AV10 65-65;
SG_MUL_VAL_ 2621308670 FlowDecAggressivenessReq_AV09 MsgType_AV09 65-65;
SG_MUL_VAL_ 2621308670 FlowDecAggressivenessReq_AV08 MsgType_AV08 65-65;
SG_MUL_VAL_ 2621308670 FlowDecAggressivenessReq_AV07 MsgType_AV07 65-65;
SG_MUL_VAL_ 2621308670 FlowDecAggressivenessReq_AV06 MsgType_AV06 65-65;
SG_MUL_VAL_ 2621308670 FlowDecAggressivenessReq_AV05 MsgType_AV05 65-65;
SG_MUL_VAL_ 2621308670 FlowDecAggressivenessReq_AV04 MsgType_AV04 65-65;
SG_MUL_VAL_ 2621308670 FlowDecAggressivenessReq_AV03 MsgType_AV03 65-65;
SG_MUL_VAL_ 2621308670 FlowDecAggressivenessReq_AV02 MsgType_AV02 65-65;
SG_MUL_VAL_ 2621308670 FlowDecAggressivenessReq_AV01 MsgType_AV01 65-65;
SG_MUL_VAL_ 2621308670 CurvatureAggressivenessReq_EG MsgType_EG 65-65;
SG_MUL_VAL_ 2621308670 SecurityByte_VS MsgType_VS 17-17;
SG_MUL_VAL_ 2621308670 SecurityByte_RTL MsgType_RTL 17-17;
SG_MUL_VAL_ 2621308670 SecurityByte_RPTO MsgType_RPTO 17-17;
SG_MUL_VAL_ 2621308670 SecurityByte_RH MsgType_RH 17-17;
SG_MUL_VAL_ 2621308670 SecurityByte_FTL MsgType_FTL 17-17;
SG_MUL_VAL_ 2621308670 SecurityByte_FPTO MsgType_FPTO 17-17;
SG_MUL_VAL_ 2621308670 SecurityByte_FH MsgType_FH 17-17;
SG_MUL_VAL_ 2621308670 SecurityByte_EG MsgType_EG 17-17;
SG_MUL_VAL_ 2621308670 SecurityByte_AV32 MsgType_AV32 17-17;
SG_MUL_VAL_ 2621308670 SecurityByte_AV31 MsgType_AV31 17-17;
SG_MUL_VAL_ 2621308670 SecurityByte_AV30 MsgType_AV30 17-17;
SG_MUL_VAL_ 2621308670 SecurityByte_AV29 MsgType_AV29 17-17;
SG_MUL_VAL_ 2621308670 SecurityByte_AV28 MsgType_AV28 17-17;
SG_MUL_VAL_ 2621308670 SecurityByte_AV27 MsgType_AV27 17-17;
SG_MUL_VAL_ 2621308670 SecurityByte_AV26 MsgType_AV26 17-17;
SG_MUL_VAL_ 2621308670 SecurityByte_AV25 MsgType_AV25 17-17;
SG_MUL_VAL_ 2621308670 SecurityByte_AV24 MsgType_AV24 17-17;
SG_MUL_VAL_ 2621308670 SecurityByte_AV23 MsgType_AV23 17-17;
SG_MUL_VAL_ 2621308670 SecurityByte_AV22 MsgType_AV22 17-17;
SG_MUL_VAL_ 2621308670 SecurityByte_AV21 MsgType_AV21 17-17;
SG_MUL_VAL_ 2621308670 SecurityByte_AV20 MsgType_AV20 17-17;
SG_MUL_VAL_ 2621308670 SecurityByte_AV19 MsgType_AV19 17-17;
SG_MUL_VAL_ 2621308670 SecurityByte_AV18 MsgType_AV18 17-17;
SG_MUL_VAL_ 2621308670 SecurityByte_AV17 MsgType_AV17 17-17;
SG_MUL_VAL_ 2621308670 SecurityByte_AV16 MsgType_AV16 17-17;
SG_MUL_VAL_ 2621308670 SecurityByte_AV15 MsgType_AV15 17-17;
SG_MUL_VAL_ 2621308670 SecurityByte_AV14 MsgType_AV14 17-17;
SG_MUL_VAL_ 2621308670 SecurityByte_AV13 MsgType_AV13 17-17;
SG_MUL_VAL_ 2621308670 SecurityByte_AV12 MsgType_AV12 17-17;
SG_MUL_VAL_ 2621308670 SecurityByte_AV11 MsgType_AV11 17-17;
SG_MUL_VAL_ 2621308670 SecurityByte_AV10 MsgType_AV10 17-17;
SG_MUL_VAL_ 2621308670 SecurityByte_AV09 MsgType_AV09 17-17;
SG_MUL_VAL_ 2621308670 SecurityByte_AV08 MsgType_AV08 17-17;
SG_MUL_VAL_ 2621308670 SecurityByte_AV07 MsgType_AV07 17-17;
SG_MUL_VAL_ 2621308670 SecurityByte_AV06 MsgType_AV06 17-17;
SG_MUL_VAL_ 2621308670 SecurityByte_AV05 MsgType_AV05 17-17;
SG_MUL_VAL_ 2621308670 SecurityByte_AV04 MsgType_AV04 17-17;
SG_MUL_VAL_ 2621308670 SecurityByte_AV03 MsgType_AV03 17-17;
SG_MUL_VAL_ 2621308670 SecurityByte_AV02 MsgType_AV02 17-17;
SG_MUL_VAL_ 2621308670 SecurityByte_AV01 MsgType_AV01 17-17;
SG_MUL_VAL_ 2621308670 PositionRequest_RTL MsgType_RTL 17-17;
SG_MUL_VAL_ 2621308670 PositionRequest_FTL MsgType_FTL 17-17;
SG_MUL_VAL_ 2621308670 ControlMode1_VS MsgType_VS 0-0;
SG_MUL_VAL_ 2621308670 ControlMode1_RTL MsgType_RTL 0-0;
SG_MUL_VAL_ 2621308670 ControlMode1_FTL MsgType_FTL 0-0;
SG_MUL_VAL_ 2621308670 NumOfControlModes_VS MsgType_VS 0-0;
SG_MUL_VAL_ 2621308670 NumOfControlModes_RTL MsgType_RTL 0-0;
SG_MUL_VAL_ 2621308670 NumOfControlModes_FTL MsgType_FTL 0-0;
SG_MUL_VAL_ 2621308670 NumOfBytes_CM1_VS MsgType_VS 0-0;
SG_MUL_VAL_ 2621308670 NumOfBytes_CM1_RTL MsgType_RTL 0-0;
SG_MUL_VAL_ 2621308670 NumOfBytes_CM1_FTL MsgType_FTL 0-0;
SG_MUL_VAL_ 2621308670 MsgType_RTL TIMFunctionID 72-72;
SG_MUL_VAL_ 2621308670 MsgType_FTL TIMFunctionID 71-71;
SG_MUL_VAL_ 2621308670 MsgType_EG TIMFunctionID 70-70;
SG_MUL_VAL_ 2621308670 MsgType_VS TIMFunctionID 68-68;
SG_MUL_VAL_ 2621308670 MsgType_RH TIMFunctionID 67-67;
SG_MUL_VAL_ 2621308670 MsgType_FH TIMFunctionID 66-66;
SG_MUL_VAL_ 2621308670 MsgType_RPTO TIMFunctionID 65-65;
SG_MUL_VAL_ 2621308670 MsgType_FPTO TIMFunctionID 64-64;
SG_MUL_VAL_ 2621308670 MsgType_AV32 TIMFunctionID 32-32;
SG_MUL_VAL_ 2621308670 MsgType_AV31 TIMFunctionID 31-31;
SG_MUL_VAL_ 2621308670 MsgType_AV30 TIMFunctionID 30-30;
SG_MUL_VAL_ 2621308670 MsgType_AV29 TIMFunctionID 29-29;
SG_MUL_VAL_ 2621308670 MsgType_AV28 TIMFunctionID 28-28;
SG_MUL_VAL_ 2621308670 MsgType_AV27 TIMFunctionID 27-27;
SG_MUL_VAL_ 2621308670 MsgType_AV26 TIMFunctionID 26-26;
SG_MUL_VAL_ 2621308670 MsgType_AV25 TIMFunctionID 25-25;
SG_MUL_VAL_ 2621308670 MsgType_AV24 TIMFunctionID 24-24;
SG_MUL_VAL_ 2621308670 MsgType_AV23 TIMFunctionID 23-23;
SG_MUL_VAL_ 2621308670 MsgType_AV22 TIMFunctionID 22-22;
SG_MUL_VAL_ 2621308670 MsgType_AV21 TIMFunctionID 21-21;
SG_MUL_VAL_ 2621308670 MsgType_AV20 TIMFunctionID 20-20;
SG_MUL_VAL_ 2621308670 MsgType_AV19 TIMFunctionID 19-19;
SG_MUL_VAL_ 2621308670 MsgType_AV18 TIMFunctionID 18-18;
SG_MUL_VAL_ 2621308670 MsgType_AV17 TIMFunctionID 17-17;
SG_MUL_VAL_ 2621308670 MsgType_AV16 TIMFunctionID 16-16;
SG_MUL_VAL_ 2621308670 MsgType_AV15 TIMFunctionID 15-15;
SG_MUL_VAL_ 2621308670 MsgType_AV14 TIMFunctionID 14-14;
SG_MUL_VAL_ 2621308670 MsgType_AV13 TIMFunctionID 13-13;
SG_MUL_VAL_ 2621308670 MsgType_AV12 TIMFunctionID 12-12;
SG_MUL_VAL_ 2621308670 MsgType_AV11 TIMFunctionID 11-11;
SG_MUL_VAL_ 2621308670 MsgType_AV10 TIMFunctionID 10-10;
SG_MUL_VAL_ 2621308670 MsgType_AV09 TIMFunctionID 9-9;
SG_MUL_VAL_ 2621308670 MsgType_AV08 TIMFunctionID 8-8;
SG_MUL_VAL_ 2621308670 MsgType_AV07 TIMFunctionID 7-7;
SG_MUL_VAL_ 2621308670 MsgType_AV06 TIMFunctionID 6-6;
SG_MUL_VAL_ 2621308670 MsgType_AV05 TIMFunctionID 5-5;
SG_MUL_VAL_ 2621308670 MsgType_AV04 TIMFunctionID 4-4;
SG_MUL_VAL_ 2621308670 MsgType_AV03 TIMFunctionID 3-3;
SG_MUL_VAL_ 2621308670 MsgType_AV02 TIMFunctionID 2-2;
SG_MUL_VAL_ 2621308670 MsgType_AV01 TIMFunctionID 1-1;
SG_MUL_VAL_ 2621308670 FlowRequest_AV32 MsgType_AV32 17-17;
SG_MUL_VAL_ 2621308670 FlowRequest_AV31 MsgType_AV31 17-17;
SG_MUL_VAL_ 2621308670 FlowRequest_AV30 MsgType_AV30 17-17;
SG_MUL_VAL_ 2621308670 FlowRequest_AV29 MsgType_AV29 17-17;
SG_MUL_VAL_ 2621308670 FlowRequest_AV28 MsgType_AV28 17-17;
SG_MUL_VAL_ 2621308670 FlowRequest_AV27 MsgType_AV27 17-17;
SG_MUL_VAL_ 2621308670 FlowRequest_AV26 MsgType_AV26 17-17;
SG_MUL_VAL_ 2621308670 FlowRequest_AV25 MsgType_AV25 17-17;
SG_MUL_VAL_ 2621308670 FlowRequest_AV24 MsgType_AV24 17-17;
SG_MUL_VAL_ 2621308670 FlowRequest_AV23 MsgType_AV23 17-17;
SG_MUL_VAL_ 2621308670 FlowRequest_AV22 MsgType_AV22 17-17;
SG_MUL_VAL_ 2621308670 FlowRequest_AV21 MsgType_AV21 17-17;
SG_MUL_VAL_ 2621308670 FlowRequest_AV20 MsgType_AV20 17-17;
SG_MUL_VAL_ 2621308670 FlowRequest_AV19 MsgType_AV19 17-17;
SG_MUL_VAL_ 2621308670 FlowRequest_AV18 MsgType_AV18 17-17;
SG_MUL_VAL_ 2621308670 FlowRequest_AV17 MsgType_AV17 17-17;
SG_MUL_VAL_ 2621308670 FlowRequest_AV16 MsgType_AV16 17-17;
SG_MUL_VAL_ 2621308670 FlowRequest_AV15 MsgType_AV15 17-17;
SG_MUL_VAL_ 2621308670 FlowRequest_AV14 MsgType_AV14 17-17;
SG_MUL_VAL_ 2621308670 FlowRequest_AV13 MsgType_AV13 17-17;
SG_MUL_VAL_ 2621308670 FlowRequest_AV12 MsgType_AV12 17-17;
SG_MUL_VAL_ 2621308670 FlowRequest_AV11 MsgType_AV11 17-17;
SG_MUL_VAL_ 2621308670 FlowRequest_AV10 MsgType_AV10 17-17;
SG_MUL_VAL_ 2621308670 FlowRequest_AV09 MsgType_AV09 17-17;
SG_MUL_VAL_ 2621308670 FlowRequest_AV08 MsgType_AV08 17-17;
SG_MUL_VAL_ 2621308670 FlowRequest_AV07 MsgType_AV07 17-17;
SG_MUL_VAL_ 2621308670 FlowRequest_AV06 MsgType_AV06 17-17;
SG_MUL_VAL_ 2621308670 FlowRequest_AV05 MsgType_AV05 17-17;
SG_MUL_VAL_ 2621308670 FlowRequest_AV04 MsgType_AV04 17-17;
SG_MUL_VAL_ 2621308670 FlowRequest_AV03 MsgType_AV03 17-17;
SG_MUL_VAL_ 2621308670 FlowRequest_AV02 MsgType_AV02 17-17;
SG_MUL_VAL_ 2621308670 PositionRequest_RH MsgType_RH 17-17;
SG_MUL_VAL_ 2621308670 OutputShaftSpeedRequest_RPTO MsgType_RPTO 17-17;
SG_MUL_VAL_ 2621308670 CurvatureRequest_EG MsgType_EG 17-17;
SG_MUL_VAL_ 2621308670 VehicleSpeedRequest_VS MsgType_VS 17-17;
SG_MUL_VAL_ 2621308670 PositionRequest_FH MsgType_FH 17-17;
SG_MUL_VAL_ 2621308670 OutputShaftSpeedRequest_FPTO MsgType_FPTO 17-17;
SG_MUL_VAL_ 2621308670 FlowRequest_AV01 MsgType_AV01 17-17;
